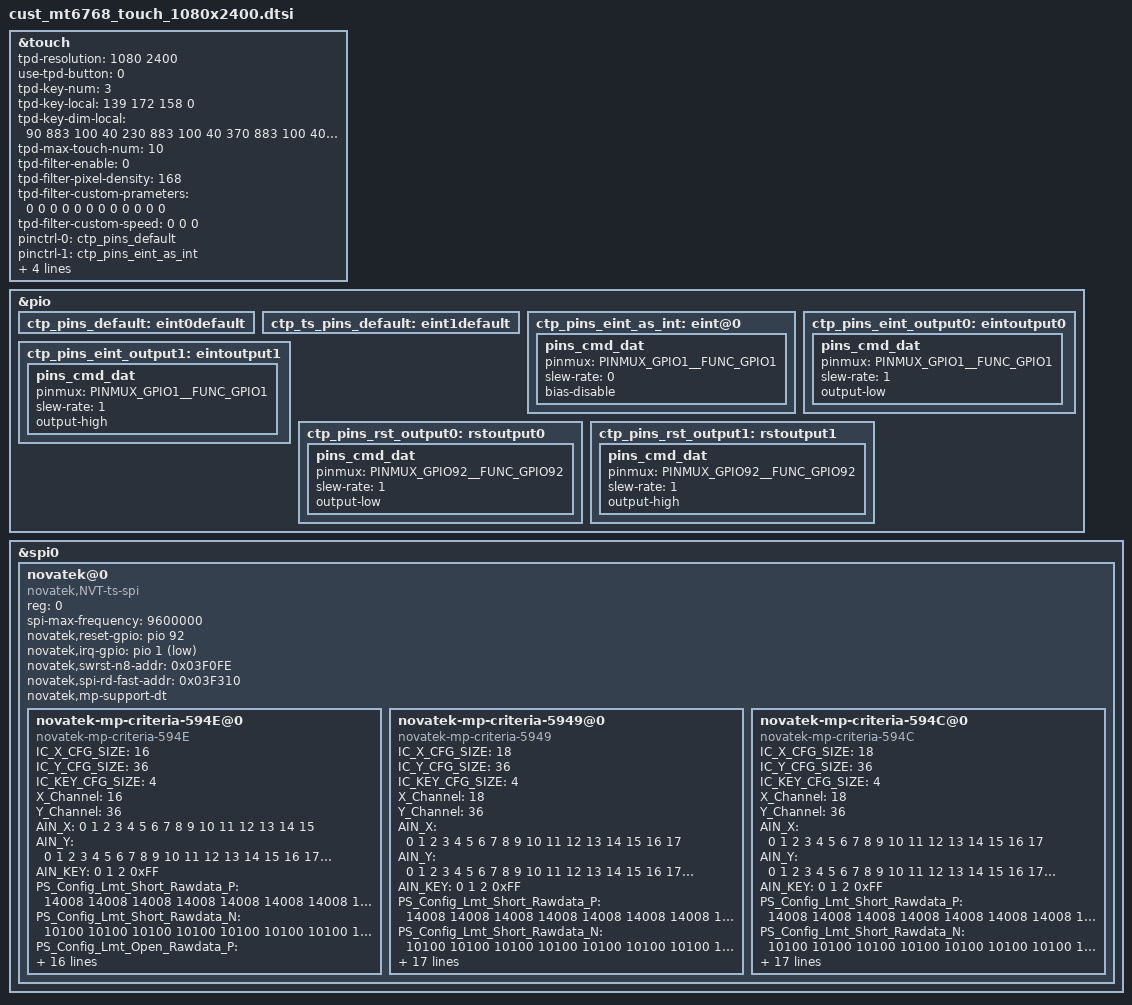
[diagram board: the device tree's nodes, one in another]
/*
 * Copyright (c) 2019 MediaTek Inc.
 *
 * This program is free software; you can redistribute it and/or modify
 * it under the terms of the GNU General Public License version 2 as
 * published by the Free Software Foundation.
 *
 * This program is distributed in the hope that it will be useful,
 * but WITHOUT ANY WARRANTY; without even the implied warranty of
 * MERCHANTABILITY or FITNESS FOR A PARTICULAR PURPOSE.  See the
 * GNU General Public License for more details.
 */
/* TOUCH start */

&touch {
	tpd-resolution = <1080 2400>;
	use-tpd-button = <0>;
	tpd-key-num = <3>;
	tpd-key-local= <139 172 158 0>;
	tpd-key-dim-local = <90 883 100 40 230
				883 100 40 370 883 100 40 0 0 0 0>;
	tpd-max-touch-num = <10>;
	tpd-filter-enable = <0>;
	tpd-filter-pixel-density = <168>;
	tpd-filter-custom-prameters = <0 0 0 0 0 0 0 0 0 0 0 0>;
	tpd-filter-custom-speed = <0 0 0>;
	pinctrl-names = "default", "state_eint_as_int",
		"state_eint_output0", "state_eint_output1",
		"state_rst_output0", "state_rst_output1";
	pinctrl-0 = <&ctp_pins_default>;
	pinctrl-1 = <&ctp_pins_eint_as_int>;
	pinctrl-2 = <&ctp_pins_eint_output0>;
	pinctrl-3 = <&ctp_pins_eint_output1>;
	pinctrl-4 = <&ctp_pins_rst_output0>;
	pinctrl-5 = <&ctp_pins_rst_output1>;
	status = "okay";
};
&pio {
	ctp_pins_default: eint0default {
	};
	ctp_ts_pins_default: eint1default {
	};
	ctp_pins_eint_as_int: eint@0 {
		pins_cmd_dat {
			pinmux = <PINMUX_GPIO1__FUNC_GPIO1>;
			slew-rate = <0>;
			bias-disable;
		};
	};
	ctp_pins_eint_output0: eintoutput0 {
		pins_cmd_dat {
			pinmux = <PINMUX_GPIO1__FUNC_GPIO1>;
			slew-rate = <1>;
			output-low;
		};
	};
	ctp_pins_eint_output1: eintoutput1 {
		pins_cmd_dat {
			pinmux = <PINMUX_GPIO1__FUNC_GPIO1>;
			slew-rate = <1>;
			output-high;
	};
	};
	ctp_pins_rst_output0: rstoutput0 {
		pins_cmd_dat {
				pinmux = <PINMUX_GPIO92__FUNC_GPIO92>;
				slew-rate = <1>;
				output-low;
			};
	};
	ctp_pins_rst_output1: rstoutput1 {
		pins_cmd_dat {
				pinmux = <PINMUX_GPIO92__FUNC_GPIO92>;
				slew-rate = <1>;
				output-high;
		};
	};

};

&spi0 {
	novatek@0 {
		compatible = "novatek,NVT-ts-spi","focaltech8719P,FTS-ts-spi";
		reg = <0>; //Same as CS ID
		status = "ok";

		spi-max-frequency = <9600000>;	//4800000,9600000,15000000,19200000
		novatek,reset-gpio = <&pio 92 0x00>;
		novatek,irq-gpio = <&pio 1 0x2001>;

		/* 525 */
		//novatek,swrst-n8-addr = <0x01F01A>;

		/* 672A, 525B, 675, 526, 672C */
		novatek,swrst-n8-addr = <0x03F0FE>;
		novatek,spi-rd-fast-addr = <0x03F310>;

		/* MP */
		novatek,mp-support-dt;

		/*36672C tr Module*/
		novatek-mp-criteria-594E@0 {
			#address-cells = <1>;
			#size-cells = <0>;
			compatible = "novatek-mp-criteria-594E";

			/* MP Config */
			IC_X_CFG_SIZE = <16>;
			IC_Y_CFG_SIZE = <36>;
			IC_KEY_CFG_SIZE = <4>;
			X_Channel = <16>;
			Y_Channel = <36>;
			AIN_X = <0 1 2 3 4 5 6 7 8 9 10 11 12 13 14 15>;
			AIN_Y = <0 1 2 3 4 5 6 7 8 9 10 11 12 13 14 15 16 17
						18 19 20 21 22 23 24 25 26 27 28 29 30 31 32 33 34 35>;
			AIN_KEY = <0 1 2 0xFF>;

			/* MP Criteria */
			PS_Config_Lmt_Short_Rawdata_P = <
				14008 14008 14008 14008 14008 14008 14008 14008 14008 14008 14008 14008 14008 14008 14008 14008
				14008 14008 14008 14008 14008 14008 14008 14008 14008 14008 14008 14008 14008 14008 14008 14008
				14008 14008 14008 14008 14008 14008 14008 14008 14008 14008 14008 14008 14008 14008 14008 14008
				14008 14008 14008 14008 14008 14008 14008 14008 14008 14008 14008 14008 14008 14008 14008 14008
				14008 14008 14008 14008 14008 14008 14008 14008 14008 14008 14008 14008 14008 14008 14008 14008
				14008 14008 14008 14008 14008 14008 14008 14008 14008 14008 14008 14008 14008 14008 14008 14008
				14008 14008 14008 14008 14008 14008 14008 14008 14008 14008 14008 14008 14008 14008 14008 14008
				14008 14008 14008 14008 14008 14008 14008 14008 14008 14008 14008 14008 14008 14008 14008 14008
				14008 14008 14008 14008 14008 14008 14008 14008 14008 14008 14008 14008 14008 14008 14008 14008
				14008 14008 14008 14008 14008 14008 14008 14008 14008 14008 14008 14008 14008 14008 14008 14008
				14008 14008 14008 14008 14008 14008 14008 14008 14008 14008 14008 14008 14008 14008 14008 14008
				14008 14008 14008 14008 14008 14008 14008 14008 14008 14008 14008 14008 14008 14008 14008 14008
				14008 14008 14008 14008 14008 14008 14008 14008 14008 14008 14008 14008 14008 14008 14008 14008
				14008 14008 14008 14008 14008 14008 14008 14008 14008 14008 14008 14008 14008 14008 14008 14008
				14008 14008 14008 14008 14008 14008 14008 14008 14008 14008 14008 14008 14008 14008 14008 14008
				14008 14008 14008 14008 14008 14008 14008 14008 14008 14008 14008 14008 14008 14008 14008 14008
				14008 14008 14008 14008 14008 14008 14008 14008 14008 14008 14008 14008 14008 14008 14008 14008
				14008 14008 14008 14008 14008 14008 14008 14008 14008 14008 14008 14008 14008 14008 14008 14008
				14008 14008 14008 14008 14008 14008 14008 14008 14008 14008 14008 14008 14008 14008 14008 14008
				14008 14008 14008 14008 14008 14008 14008 14008 14008 14008 14008 14008 14008 14008 14008 14008
				14008 14008 14008 14008 14008 14008 14008 14008 14008 14008 14008 14008 14008 14008 14008 14008
				14008 14008 14008 14008 14008 14008 14008 14008 14008 14008 14008 14008 14008 14008 14008 14008
				14008 14008 14008 14008 14008 14008 14008 14008 14008 14008 14008 14008 14008 14008 14008 14008
				14008 14008 14008 14008 14008 14008 14008 14008 14008 14008 14008 14008 14008 14008 14008 14008
				14008 14008 14008 14008 14008 14008 14008 14008 14008 14008 14008 14008 14008 14008 14008 14008
				14008 14008 14008 14008 14008 14008 14008 14008 14008 14008 14008 14008 14008 14008 14008 14008
				14008 14008 14008 14008 14008 14008 14008 14008 14008 14008 14008 14008 14008 14008 14008 14008
				14008 14008 14008 14008 14008 14008 14008 14008 14008 14008 14008 14008 14008 14008 14008 14008
				14008 14008 14008 14008 14008 14008 14008 14008 14008 14008 14008 14008 14008 14008 14008 14008
				14008 14008 14008 14008 14008 14008 14008 14008 14008 14008 14008 14008 14008 14008 14008 14008
				14008 14008 14008 14008 14008 14008 14008 14008 14008 14008 14008 14008 14008 14008 14008 14008
				14008 14008 14008 14008 14008 14008 14008 14008 14008 14008 14008 14008 14008 14008 14008 14008
				14008 14008 14008 14008 14008 14008 14008 14008 14008 14008 14008 14008 14008 14008 14008 14008
				14008 14008 14008 14008 14008 14008 14008 14008 14008 14008 14008 14008 14008 14008 14008 14008
				14008 14008 14008 14008 14008 14008 14008 14008 14008 14008 14008 14008 14008 14008 14008 14008
				14008 14008 14008 14008 14008 14008 14008 14008 14008 14008 14008 14008 14008 14008 14008 14008
				14008 14008 14008>;

			PS_Config_Lmt_Short_Rawdata_N = <
				10100 10100 10100 10100 10100 10100 10100 10100 10100 10100 10100 10100 10100 10100 10100 10100
				10100 10100 10100 10100 10100 10100 10100 10100 10100 10100 10100 10100 10100 10100 10100 10100
				10100 10100 10100 10100 10100 10100 10100 10100 10100 10100 10100 10100 10100 10100 10100 10100
				10100 10100 10100 10100 10100 10100 10100 10100 10100 10100 10100 10100 10100 10100 10100 10100
				10100 10100 10100 10100 10100 10100 10100 10100 10100 10100 10100 10100 10100 10100 10100 10100
				10100 10100 10100 10100 10100 10100 10100 10100 10100 10100 10100 10100 10100 10100 10100 10100
				10100 10100 10100 10100 10100 10100 10100 10100 10100 10100 10100 10100 10100 10100 10100 10100
				10100 10100 10100 10100 10100 10100 10100 10100 10100 10100 10100 10100 10100 10100 10100 10100
				10100 10100 10100 10100 10100 10100 10100 10100 10100 10100 10100 10100 10100 10100 10100 10100
				10100 10100 10100 10100 10100 10100 10100 10100 10100 10100 10100 10100 10100 10100 10100 10100
				10100 10100 10100 10100 10100 10100 10100 10100 10100 10100 10100 10100 10100 10100 10100 10100
				10100 10100 10100 10100 10100 10100 10100 10100 10100 10100 10100 10100 10100 10100 10100 10100
				10100 10100 10100 10100 10100 10100 10100 10100 10100 10100 10100 10100 10100 10100 10100 10100
				10100 10100 10100 10100 10100 10100 10100 10100 10100 10100 10100 10100 10100 10100 10100 10100
				10100 10100 10100 10100 10100 10100 10100 10100 10100 10100 10100 10100 10100 10100 10100 10100
				10100 10100 10100 10100 10100 10100 10100 10100 10100 10100 10100 10100 10100 10100 10100 10100
				10100 10100 10100 10100 10100 10100 10100 10100 10100 10100 10100 10100 10100 10100 10100 10100
				10100 10100 10100 10100 10100 10100 10100 10100 10100 10100 10100 10100 10100 10100 10100 10100
				10100 10100 10100 10100 10100 10100 10100 10100 10100 10100 10100 10100 10100 10100 10100 10100
				10100 10100 10100 10100 10100 10100 10100 10100 10100 10100 10100 10100 10100 10100 10100 10100
				10100 10100 10100 10100 10100 10100 10100 10100 10100 10100 10100 10100 10100 10100 10100 10100
				10100 10100 10100 10100 10100 10100 10100 10100 10100 10100 10100 10100 10100 10100 10100 10100
				10100 10100 10100 10100 10100 10100 10100 10100 10100 10100 10100 10100 10100 10100 10100 10100
				10100 10100 10100 10100 10100 10100 10100 10100 10100 10100 10100 10100 10100 10100 10100 10100
				10100 10100 10100 10100 10100 10100 10100 10100 10100 10100 10100 10100 10100 10100 10100 10100
				10100 10100 10100 10100 10100 10100 10100 10100 10100 10100 10100 10100 10100 10100 10100 10100
				10100 10100 10100 10100 10100 10100 10100 10100 10100 10100 10100 10100 10100 10100 10100 10100
				10100 10100 10100 10100 10100 10100 10100 10100 10100 10100 10100 10100 10100 10100 10100 10100
				10100 10100 10100 10100 10100 10100 10100 10100 10100 10100 10100 10100 10100 10100 10100 10100
				10100 10100 10100 10100 10100 10100 10100 10100 10100 10100 10100 10100 10100 10100 10100 10100
				10100 10100 10100 10100 10100 10100 10100 10100 10100 10100 10100 10100 10100 10100 10100 10100
				10100 10100 10100 10100 10100 10100 10100 10100 10100 10100 10100 10100 10100 10100 10100 10100
				10100 10100 10100 10100 10100 10100 10100 10100 10100 10100 10100 10100 10100 10100 10100 10100
				10100 10100 10100 10100 10100 10100 10100 10100 10100 10100 10100 10100 10100 10100 10100 10100
				10100 10100 10100 10100 10100 10100 10100 10100 10100 10100 10100 10100 10100 10100 10100 10100
				10100 10100 10100 10100 10100 10100 10100 10100 10100 10100 10100 10100 10100 10100 10100 10100
				10000 10000 10000>;

			PS_Config_Lmt_Open_Rawdata_P = <
				3693 4146 4086 4022 3992 3977 3984 3880 4044 4183 4170 4183 4118 4131 4132 3676
				3915 4151 4062 3997 3970 3959 3963 3906 4111 4198 4181 4205 4138 4152 4179 3911
				4102 4109 4018 3946 3922 3906 3915 3896 4050 4065 4058 4074 4023 4040 4085 4025
				4082 4088 3997 3914 3889 3871 3885 3829 4054 4078 4064 4085 4046 4060 4116 4025
				4015 4032 3931 3855 3838 3813 3826 3801 3953 3980 3976 3988 3948 3983 4030 3981
				3974 3994 3883 3824 3796 3773 3785 3760 3899 3927 3920 3931 3907 3945 3991 3945
				3976 4001 3897 3822 3801 3782 3791 3767 3901 3931 3918 3941 3918 3953 4009 3966
				3970 4005 3897 3817 3796 3782 3757 3766 3855 3886 3869 3889 3868 3907 3932 3922
				3956 3987 3883 3803 3785 3764 3782 3756 3802 3823 3813 3826 3819 3855 3925 3878
				3903 3934 3830 3747 3732 3711 3726 3700 3809 3827 3820 3831 3830 3868 3945 3894
				3879 3924 3809 3735 3714 3668 3710 3686 3771 3796 3788 3796 3799 3813 3913 3873
				3861 3897 3785 3712 3694 3676 3694 3672 3739 3767 3757 3766 3774 3823 3893 3857
				3833 3876 3771 3687 3668 3654 3666 3641 3677 3708 3693 3707 3721 3764 3843 3802
				3798 3840 3743 3656 3640 3627 3631 3606 3649 3679 3662 3680 3693 3739 3819 3780
				3764 3801 3708 3619 3579 3589 3602 3571 3621 3645 3638 3651 3644 3721 3801 3761
				3717 3749 3661 3572 3554 3539 3551 3523 3544 3567 3563 3571 3596 3648 3738 3693
				3658 3698 3609 3523 3505 3491 3500 3474 3533 3560 3551 3563 3581 3648 3729 3693
				3640 3679 3581 3476 3479 3465 3473 3452 3484 3512 3504 3488 3535 3606 3687 3652
				3606 3644 3556 3494 3474 3467 3472 3448 3393 3417 3409 3414 3439 3530 3627 3598
				3565 3598 3508 3446 3431 3424 3424 3407 3372 3395 3388 3400 3420 3512 3612 3586
				3533 3558 3469 3411 3397 3386 3389 3368 3312 3330 3330 3336 3358 3448 3560 3529
				3498 3518 3409 3374 3358 3343 3344 3326 3277 3292 3274 3304 3329 3418 3532 3504
				3458 3484 3389 3334 3323 3313 3308 3292 3183 3203 3208 3215 3236 3330 3446 3424
				3410 3430 3333 3277 3270 3262 3253 3241 3155 3175 3183 3186 3207 3304 3420 3402
				3364 3386 3291 3232 3225 3218 3214 3196 3101 3119 3119 3130 3152 3243 3371 3350
				3319 3322 3249 3186 3185 3179 3172 3155 3061 3063 3081 3092 3110 3203 3334 3313
				3283 3304 3208 3145 3147 3136 3134 3113 3010 3026 3032 3039 3056 3148 3280 3263
				3227 3243 3145 3084 3085 3074 3073 3053 2962 2976 2987 2991 3014 3103 3238 3224
				3158 3194 3092 3032 3036 3029 3024 3008 2892 2921 2926 2933 2952 3045 3173 3168
				3131 3154 3047 2989 2991 2986 2979 2966 2849 2871 2875 2882 2900 2994 3123 3124
				3101 3116 3015 2951 2961 2955 2949 2931 2795 2814 2816 2826 2844 2934 3066 3067
				3038 3053 2956 2889 2900 2895 2889 2871 2760 2780 2783 2791 2809 2898 3028 3038
				3059 3073 2969 2902 2916 2910 2906 2886 2748 2769 2774 2777 2797 2892 3024 3036
				2977 2993 2889 2822 2836 2830 2830 2814 2678 2695 2699 2699 2718 2818 2949 2961
				2702 2962 2851 2786 2805 2801 2800 2783 2672 2695 2693 2695 2714 2812 2952 2721
				2857 2920 2804 2739 2758 2755 2758 2742 2597 2622 2615 2618 2637 2737 2871 2847
				5120 5120 5120>;

			PS_Config_Lmt_Open_Rawdata_N = <
				1582 1777 1751 1723 1711 1704 1707 1663 1733 1792 1787 1792 1765 1770 1771 1575
				1678 1779 1741 1713 1701 1696 1698 1674 1762 1799 1792 1802 1773 1779 1791 1676
				1758 1761 1722 1691 1681 1674 1678 1669 1735 1742 1739 1746 1724 1731 1750 1725
				1749 1752 1713 1677 1666 1659 1665 1641 1737 1747 1741 1750 1734 1740 1764 1725
				1720 1728 1684 1652 1645 1634 1639 1629 1694 1705 1704 1709 1692 1707 1727 1706
				1703 1711 1664 1639 1627 1617 1622 1611 1671 1683 1680 1684 1674 1690 1710 1690
				1704 1714 1670 1638 1629 1621 1624 1614 1672 1684 1679 1689 1679 1694 1718 1699
				1701 1716 1670 1636 1627 1621 1610 1614 1652 1665 1658 1666 1657 1674 1685 1681
				1695 1708 1664 1630 1622 1613 1621 1609 1629 1638 1634 1639 1636 1652 1682 1662
				1672 1686 1641 1606 1599 1590 1597 1585 1632 1640 1637 1642 1641 1657 1690 1669
				1662 1681 1632 1600 1591 1572 1590 1579 1616 1627 1623 1627 1628 1634 1677 1660
				1654 1670 1622 1591 1583 1575 1583 1573 1602 1614 1610 1614 1617 1638 1668 1653
				1642 1661 1616 1580 1572 1566 1571 1560 1576 1589 1582 1588 1594 1613 1647 1629
				1627 1645 1604 1567 1560 1554 1556 1545 1564 1576 1569 1577 1582 1602 1636 1620
				1613 1629 1589 1551 1534 1538 1543 1530 1552 1562 1559 1564 1561 1594 1629 1612
				1593 1606 1569 1531 1523 1516 1522 1510 1519 1528 1527 1530 1541 1563 1602 1582
				1567 1585 1546 1510 1502 1496 1500 1489 1514 1525 1522 1527 1534 1563 1598 1582
				1560 1576 1534 1489 1491 1485 1488 1479 1493 1505 1501 1495 1515 1545 1580 1565
				1545 1561 1524 1497 1489 1486 1488 1477 1454 1464 1461 1463 1474 1513 1554 1542
				1528 1542 1503 1477 1470 1467 1467 1460 1445 1455 1452 1457 1465 1505 1548 1537
				1514 1525 1486 1462 1456 1451 1452 1443 1419 1427 1427 1429 1439 1477 1525 1512
				1499 1507 1461 1446 1439 1432 1433 1425 1404 1411 1403 1416 1426 1465 1513 1501
				1482 1493 1452 1429 1424 1420 1417 1411 1364 1372 1375 1378 1387 1427 1477 1467
				1461 1470 1428 1404 1401 1398 1394 1389 1352 1360 1364 1365 1374 1416 1465 1458
				1441 1451 1410 1385 1382 1379 1377 1369 1329 1336 1336 1341 1351 1390 1444 1435
				1422 1423 1392 1365 1365 1362 1359 1352 1312 1312 1320 1325 1333 1372 1429 1420
				1407 1416 1375 1348 1348 1344 1343 1334 1290 1297 1299 1302 1309 1349 1405 1398
				1383 1390 1348 1321 1322 1317 1317 1308 1269 1275 1280 1282 1291 1330 1387 1381
				1353 1369 1325 1299 1301 1298 1296 1289 1239 1252 1254 1257 1265 1305 1360 1357
				1342 1351 1306 1281 1282 1279 1276 1271 1221 1230 1232 1235 1243 1283 1338 1339
				1329 1335 1292 1264 1269 1266 1264 1256 1198 1206 1207 1211 1219 1257 1314 1314
				1302 1308 1267 1238 1243 1240 1238 1230 1183 1191 1192 1196 1204 1242 1297 1302
				1311 1317 1272 1243 1249 1247 1245 1237 1177 1186 1189 1190 1198 1239 1296 1301
				1276 1282 1238 1209 1215 1213 1213 1206 1147 1155 1156 1156 1165 1207 1264 1269
				1158 1269 1222 1194 1202 1200 1200 1192 1145 1155 1154 1155 1163 1205 1265 1166
				1224 1251 1201 1174 1182 1180 1182 1175 1113 1123 1120 1122 1130 1173 1230 1220
				(-511) (-511) (-511)>;

			PS_Config_Lmt_FW_Rawdata_P = <
				1125 1124 1125 1122 1121 1127 1125 1127 1104 1106 1107 1114 1110 1106 1101 1114
				1118 1111 1110 1114 1113 1117 1120 1118 1120 1115 1115 1106 1104 1101 1097 1115
				1125 1108 1113 1118 1113 1113 1115 1108 1120 1106 1114 1117 1111 1124 1118 1099
				1100 1132 1131 1136 1120 1118 1141 1127 1099 1106 1103 1085 1089 1118 1122 1087
				1139 1124 1120 1132 1114 1106 1129 1120 1117 1121 1122 1125 1125 1121 1117 1113
				1120 1117 1115 1113 1104 1106 1111 1114 1114 1107 1129 1120 1115 1125 1131 1110
				1110 1131 1122 1121 1113 1117 1114 1114 1103 1104 1125 1125 1125 1131 1134 1097
				1132 1111 1111 1110 1114 1114 1110 1113 1129 1134 1124 1129 1134 1120 1115 1120
				1135 1122 1122 1120 1115 1111 1120 1114 1136 1132 1124 1120 1124 1125 1118 1127
				1129 1117 1113 1110 1121 1117 1120 1125 1101 1111 1118 1121 1118 1129 1125 1104
				1114 1113 1111 1111 1111 1107 1117 1118 1122 1124 1125 1125 1122 1132 1124 1128
				1108 1125 1129 1127 1127 1122 1121 1118 1132 1132 1122 1125 1120 1124 1115 1131
				1129 1115 1121 1113 1115 1113 1113 1113 1139 1135 1132 1131 1128 1134 1121 1125
				1103 1148 1155 1145 1134 1149 1156 1155 1122 1127 1122 1108 1121 1125 1120 1121
				1132 1121 1118 1117 1129 1114 1120 1122 1127 1118 1111 1117 1104 1104 1103 1121
				1099 1122 1110 1118 1111 1103 1113 1106 1107 1106 1104 1108 1106 1096 1096 1101
				1111 1108 1114 1107 1111 1106 1114 1113 1138 1132 1127 1134 1124 1131 1121 1146
				1121 1122 1129 1128 1115 1121 1129 1115 1096 1097 1111 1129 1110 1111 1134 1108
				1117 1117 1122 1121 1124 1118 1114 1115 1120 1106 1104 1108 1107 1107 1111 1127
				1135 1124 1122 1125 1125 1134 1135 1124 1117 1110 1121 1118 1121 1115 1120 1107
				1106 1103 1110 1110 1103 1108 1103 1108 1141 1104 1100 1099 1097 1099 1097 1138
				1131 1113 1132 1115 1115 1124 1134 1129 1113 1114 1114 1111 1110 1113 1111 1120
				1129 1104 1099 1104 1104 1100 1106 1103 1100 1125 1118 1118 1121 1117 1114 1106
				1118 1117 1117 1120 1117 1118 1120 1129 1128 1132 1122 1124 1124 1128 1125 1115
				1122 1097 1092 1093 1096 1094 1096 1099 1120 1110 1120 1111 1108 1108 1113 1120
				1111 1135 1129 1135 1131 1129 1127 1107 1106 1106 1101 1100 1100 1108 1103 1110
				1135 1120 1122 1121 1121 1127 1125 1129 1134 1122 1128 1117 1120 1120 1118 1136
				1108 1124 1121 1118 1124 1117 1110 1101 1111 1111 1115 1113 1115 1118 1118 1120
				1111 1106 1101 1099 1113 1104 1103 1118 1115 1118 1115 1124 1117 1113 1121 1115
				1124 1129 1129 1131 1125 1138 1131 1108 1121 1121 1125 1118 1114 1117 1121 1124
				1111 1114 1110 1111 1107 1113 1107 1106 1113 1113 1114 1106 1115 1107 1107 1125
				1106 1090 1080 1083 1085 1087 1083 1131 1115 1149 1150 1146 1149 1146 1142 1108
				1115 1121 1122 1124 1127 1122 1118 1108 1111 1135 1131 1117 1128 1122 1122 1127
				1103 1129 1120 1115 1122 1101 1099 1106 1114 1111 1117 1129 1127 1136 1129 1107
				1141 1134 1141 1141 1139 1141 1139 1124 1124 1108 1103 1122 1120 1120 1118 1113
				1092 1113 1118 1106 1115 1127 1111 1097 1118 1118 1117 1124 1122 1115 1117 1107
				2560 2560 2560>;

			PS_Config_Lmt_FW_Rawdata_N = <
				482 481 482 481 480 483 482 483 473 474 474 477 475 474 472 477
				479 476 475 477 477 478 480 479 480 478 478 474 473 472 470 478
				482 475 477 479 477 477 478 475 480 474 477 478 476 481 479 471
				471 485 484 487 480 479 489 483 471 474 472 465 466 479 481 466
				488 481 480 485 477 474 484 480 478 480 481 482 482 480 478 477
				480 478 478 477 473 474 476 477 477 474 484 480 478 482 484 475
				475 484 481 480 477 478 477 477 472 473 482 482 482 484 486 470
				485 476 476 475 477 477 475 477 484 486 481 484 486 480 478 480
				486 481 481 480 478 476 480 477 487 485 481 480 481 482 479 483
				484 478 477 475 480 478 480 482 472 476 479 480 479 484 482 473
				477 477 476 476 476 474 478 479 481 481 482 482 481 485 481 483
				475 482 484 483 483 481 480 479 485 485 481 482 480 481 478 484
				484 478 480 477 478 477 477 477 488 486 485 484 483 486 480 482
				472 492 495 490 486 492 495 495 481 483 481 475 480 482 480 480
				485 480 479 478 484 477 480 481 483 479 476 478 473 473 472 480
				471 481 475 479 476 472 477 474 474 474 473 475 474 469 469 472
				476 475 477 474 476 474 477 477 487 485 483 486 481 484 480 491
				480 481 484 483 478 480 484 478 469 470 476 484 475 476 486 475
				478 478 481 480 481 479 477 478 480 474 473 475 474 474 476 483
				486 481 481 482 482 486 486 481 478 475 480 479 480 478 480 474
				474 472 475 475 472 475 472 475 489 473 471 471 470 471 470 487
				484 477 485 478 478 481 486 484 477 477 477 476 475 477 476 480
				484 473 471 473 473 471 474 472 471 482 479 479 480 478 477 474
				479 478 478 480 478 479 480 484 483 485 481 481 481 483 482 478
				481 470 468 468 469 469 469 471 480 475 480 476 475 475 477 480
				476 486 484 486 484 484 483 474 474 474 472 471 471 475 472 475
				486 480 481 480 480 483 482 484 486 481 483 478 480 480 479 487
				475 481 480 479 481 478 475 472 476 476 478 477 478 479 479 480
				476 474 472 471 477 473 472 479 478 479 478 481 478 477 480 478
				481 484 484 484 482 487 484 475 480 480 482 479 477 478 480 481
				476 477 475 476 474 477 474 474 477 477 477 474 478 474 474 482
				474 467 463 464 465 466 464 484 478 492 493 491 492 491 489 475
				478 480 481 481 483 481 479 475 476 486 484 478 483 481 481 483
				472 484 480 478 481 472 471 474 477 476 478 484 483 487 484 474
				489 486 489 489 488 489 488 481 481 475 472 481 480 480 479 477
				468 477 479 474 478 483 476 470 479 479 478 481 481 478 478 474
				240 240 240>;

			PS_Config_Lmt_FW_CC_P = <
				41 40 40 40 40 40 40 40 40 40 40 40 40 40 40 41
				41 40 40 40 40 40 40 40 40 40 40 40 40 40 40 40
				40 40 40 40 40 40 40 40 40 40 40 40 40 40 40 40
				41 40 40 40 40 40 40 40 40 40 40 40 40 40 40 40
				40 40 40 40 40 40 40 40 40 40 40 40 40 40 40 40
				41 40 40 40 40 40 40 40 40 40 40 40 40 40 40 40
				40 40 40 40 40 40 40 40 40 40 40 40 40 40 40 41
				41 41 40 41 40 40 41 41 40 40 40 40 40 40 40 40
				41 40 40 40 40 40 40 41 40 40 40 40 40 40 40 41
				41 41 41 41 41 41 41 41 40 40 40 40 40 40 40 40
				41 40 40 40 40 40 40 40 41 41 41 41 41 40 40 41
				41 40 40 40 40 40 41 41 40 40 40 40 40 40 40 40
				41 40 40 40 40 40 40 40 40 40 40 40 40 40 40 41
				41 40 40 40 41 40 41 41 41 41 40 41 40 40 40 40
				41 40 41 40 41 40 41 41 41 41 40 41 41 41 40 41
				41 41 41 41 41 41 41 41 41 41 40 40 40 41 40 41
				40 40 40 40 40 40 40 40 41 41 41 41 41 41 41 41
				41 40 40 40 41 41 41 41 41 41 41 40 41 41 40 41
				41 40 40 40 40 41 41 41 41 41 41 40 40 40 40 41
				41 41 41 41 41 41 41 41 41 41 41 41 41 41 41 41
				40 40 40 40 40 40 40 40 41 41 40 40 40 40 40 41
				41 41 41 41 41 41 41 41 41 41 41 41 41 41 41 41
				41 40 40 40 40 40 40 41 41 40 40 40 40 40 40 41
				41 41 41 41 41 41 41 41 40 40 40 40 40 40 40 41
				41 40 40 40 40 40 40 40 41 40 40 40 40 40 40 41
				41 41 41 41 41 41 41 41 41 41 41 41 41 41 41 41
				41 40 40 40 40 41 41 41 41 41 41 41 41 41 41 41
				41 41 41 41 41 41 41 41 41 41 41 41 41 41 41 41
				41 41 41 41 41 41 41 41 41 41 41 40 41 41 41 41
				41 41 41 41 41 41 41 41 41 41 41 41 41 41 41 41
				41 41 41 41 41 41 41 41 41 41 41 41 41 41 41 41
				41 41 41 41 41 41 41 41 41 41 41 40 41 41 40 41
				41 41 41 41 41 41 41 41 41 41 41 41 41 41 41 41
				41 41 41 41 41 41 41 41 41 41 41 40 41 40 40 41
				41 40 41 41 41 41 41 41 41 41 41 41 41 41 41 41
				42 41 41 41 41 41 41 42 41 41 41 41 41 41 41 42
				314 314 314>;

			PS_Config_Lmt_FW_CC_N = <
				18 17 17 17 17 17 17 17 17 17 17 17 17 17 17 18
				18 17 17 17 17 17 17 17 17 17 17 17 17 17 17 17
				17 17 17 17 17 17 17 17 17 17 17 17 17 17 17 17
				18 17 17 17 17 17 17 17 17 17 17 17 17 17 17 17
				17 17 17 17 17 17 17 17 17 17 17 17 17 17 17 17
				18 17 17 17 17 17 17 17 17 17 17 17 17 17 17 17
				17 17 17 17 17 17 17 17 17 17 17 17 17 17 17 18
				18 18 17 18 17 17 18 18 17 17 17 17 17 17 17 17
				18 17 17 17 17 17 17 18 17 17 17 17 17 17 17 18
				18 18 18 18 18 18 18 18 17 17 17 17 17 17 17 17
				18 17 17 17 17 17 17 17 18 18 18 18 18 17 17 18
				18 17 17 17 17 17 18 18 17 17 17 17 17 17 17 17
				18 17 17 17 17 17 17 17 17 17 17 17 17 17 17 18
				18 17 17 17 18 17 18 18 18 18 17 18 17 17 17 17
				18 17 18 17 18 17 18 18 18 18 17 18 18 18 17 18
				18 18 18 18 18 18 18 18 18 18 17 17 17 18 17 18
				17 17 17 17 17 17 17 17 18 18 18 18 18 18 18 18
				18 17 17 17 18 18 18 18 18 18 18 17 18 18 17 18
				18 17 17 17 17 18 18 18 18 18 18 17 17 17 17 18
				18 18 18 18 18 18 18 18 18 18 18 18 18 18 18 18
				17 17 17 17 17 17 17 17 18 18 17 17 17 17 17 18
				18 18 18 18 18 18 18 18 18 18 18 18 18 18 18 18
				18 17 17 17 17 17 17 18 18 17 17 17 17 17 17 18
				18 18 18 18 18 18 18 18 17 17 17 17 17 17 17 18
				18 17 17 17 17 17 17 17 18 17 17 17 17 17 17 18
				18 18 18 18 18 18 18 18 18 18 18 18 18 18 18 18
				18 17 17 17 17 18 18 18 18 18 18 18 18 18 18 18
				18 18 18 18 18 18 18 18 18 18 18 18 18 18 18 18
				18 18 18 18 18 18 18 18 18 18 18 17 18 18 18 18
				18 18 18 18 18 18 18 18 18 18 18 18 18 18 18 18
				18 18 18 18 18 18 18 18 18 18 18 18 18 18 18 18
				18 18 18 18 18 18 18 18 18 18 18 17 18 18 17 18
				18 18 18 18 18 18 18 18 18 18 18 18 18 18 18 18
				18 18 18 18 18 18 18 18 18 18 18 17 18 17 17 18
				18 17 18 18 18 18 18 18 18 18 18 18 18 18 18 18
				19 18 18 18 18 18 18 19 18 18 18 18 18 18 18 19
				0 0 0>;

			PS_Config_Lmt_FW_Diff_P = <
				50 50 50 50 50 50 50 50 50 50 50 50 50 50 50 50
				50 50 50 50 50 50 50 50 50 50 50 50 50 50 50 50
				50 50 50 50 50 50 50 50 50 50 50 50 50 50 50 50
				50 50 50 50 50 50 50 50 50 50 50 50 50 50 50 50
				50 50 50 50 50 50 50 50 50 50 50 50 50 50 50 50
				50 50 50 50 50 50 50 50 50 50 50 50 50 50 50 50
				50 50 50 50 50 50 50 50 50 50 50 50 50 50 50 50
				50 50 50 50 50 50 50 50 50 50 50 50 50 50 50 50
				50 50 50 50 50 50 50 50 50 50 50 50 50 50 50 50
				50 50 50 50 50 50 50 50 50 50 50 50 50 50 50 50
				50 50 50 50 50 50 50 50 50 50 50 50 50 50 50 50
				50 50 50 50 50 50 50 50 50 50 50 50 50 50 50 50
				50 50 50 50 50 50 50 50 50 50 50 50 50 50 50 50
				50 50 50 50 50 50 50 50 50 50 50 50 50 50 50 50
				50 50 50 50 50 50 50 50 50 50 50 50 50 50 50 50
				50 50 50 50 50 50 50 50 50 50 50 50 50 50 50 50
				50 50 50 50 50 50 50 50 50 50 50 50 50 50 50 50
				50 50 50 50 50 50 50 50 50 50 50 50 50 50 50 50
				50 50 50 50 50 50 50 50 50 50 50 50 50 50 50 50
				50 50 50 50 50 50 50 50 50 50 50 50 50 50 50 50
				50 50 50 50 50 50 50 50 50 50 50 50 50 50 50 50
				50 50 50 50 50 50 50 50 50 50 50 50 50 50 50 50
				50 50 50 50 50 50 50 50 50 50 50 50 50 50 50 50
				50 50 50 50 50 50 50 50 50 50 50 50 50 50 50 50
				50 50 50 50 50 50 50 50 50 50 50 50 50 50 50 50
				50 50 50 50 50 50 50 50 50 50 50 50 50 50 50 50
				50 50 50 50 50 50 50 50 50 50 50 50 50 50 50 50
				50 50 50 50 50 50 50 50 50 50 50 50 50 50 50 50
				50 50 50 50 50 50 50 50 50 50 50 50 50 50 50 50
				50 50 50 50 50 50 50 50 50 50 50 50 50 50 50 50
				50 50 50 50 50 50 50 50 50 50 50 50 50 50 50 50
				50 50 50 50 50 50 50 50 50 50 50 50 50 50 50 50
				50 50 50 50 50 50 50 50 50 50 50 50 50 50 50 50
				50 50 50 50 50 50 50 50 50 50 50 50 50 50 50 50
				50 50 50 50 50 50 50 50 50 50 50 50 50 50 50 50
				50 50 50 50 50 50 50 50 50 50 50 50 50 50 50 50
				75 75 75>;

			PS_Config_Lmt_FW_Diff_N = <
				(-50) (-50) (-50) (-50) (-50) (-50) (-50) (-50) (-50) (-50) (-50) (-50) (-50) (-50) (-50) (-50)
				(-50) (-50) (-50) (-50) (-50) (-50) (-50) (-50) (-50) (-50) (-50) (-50) (-50) (-50) (-50) (-50)
				(-50) (-50) (-50) (-50) (-50) (-50) (-50) (-50) (-50) (-50) (-50) (-50) (-50) (-50) (-50) (-50)
				(-50) (-50) (-50) (-50) (-50) (-50) (-50) (-50) (-50) (-50) (-50) (-50) (-50) (-50) (-50) (-50)
				(-50) (-50) (-50) (-50) (-50) (-50) (-50) (-50) (-50) (-50) (-50) (-50) (-50) (-50) (-50) (-50)
				(-50) (-50) (-50) (-50) (-50) (-50) (-50) (-50) (-50) (-50) (-50) (-50) (-50) (-50) (-50) (-50)
				(-50) (-50) (-50) (-50) (-50) (-50) (-50) (-50) (-50) (-50) (-50) (-50) (-50) (-50) (-50) (-50)
				(-50) (-50) (-50) (-50) (-50) (-50) (-50) (-50) (-50) (-50) (-50) (-50) (-50) (-50) (-50) (-50)
				(-50) (-50) (-50) (-50) (-50) (-50) (-50) (-50) (-50) (-50) (-50) (-50) (-50) (-50) (-50) (-50)
				(-50) (-50) (-50) (-50) (-50) (-50) (-50) (-50) (-50) (-50) (-50) (-50) (-50) (-50) (-50) (-50)
				(-50) (-50) (-50) (-50) (-50) (-50) (-50) (-50) (-50) (-50) (-50) (-50) (-50) (-50) (-50) (-50)
				(-50) (-50) (-50) (-50) (-50) (-50) (-50) (-50) (-50) (-50) (-50) (-50) (-50) (-50) (-50) (-50)
				(-50) (-50) (-50) (-50) (-50) (-50) (-50) (-50) (-50) (-50) (-50) (-50) (-50) (-50) (-50) (-50)
				(-50) (-50) (-50) (-50) (-50) (-50) (-50) (-50) (-50) (-50) (-50) (-50) (-50) (-50) (-50) (-50)
				(-50) (-50) (-50) (-50) (-50) (-50) (-50) (-50) (-50) (-50) (-50) (-50) (-50) (-50) (-50) (-50)
				(-50) (-50) (-50) (-50) (-50) (-50) (-50) (-50) (-50) (-50) (-50) (-50) (-50) (-50) (-50) (-50)
				(-50) (-50) (-50) (-50) (-50) (-50) (-50) (-50) (-50) (-50) (-50) (-50) (-50) (-50) (-50) (-50)
				(-50) (-50) (-50) (-50) (-50) (-50) (-50) (-50) (-50) (-50) (-50) (-50) (-50) (-50) (-50) (-50)
				(-50) (-50) (-50) (-50) (-50) (-50) (-50) (-50) (-50) (-50) (-50) (-50) (-50) (-50) (-50) (-50)
				(-50) (-50) (-50) (-50) (-50) (-50) (-50) (-50) (-50) (-50) (-50) (-50) (-50) (-50) (-50) (-50)
				(-50) (-50) (-50) (-50) (-50) (-50) (-50) (-50) (-50) (-50) (-50) (-50) (-50) (-50) (-50) (-50)
				(-50) (-50) (-50) (-50) (-50) (-50) (-50) (-50) (-50) (-50) (-50) (-50) (-50) (-50) (-50) (-50)
				(-50) (-50) (-50) (-50) (-50) (-50) (-50) (-50) (-50) (-50) (-50) (-50) (-50) (-50) (-50) (-50)
				(-50) (-50) (-50) (-50) (-50) (-50) (-50) (-50) (-50) (-50) (-50) (-50) (-50) (-50) (-50) (-50)
				(-50) (-50) (-50) (-50) (-50) (-50) (-50) (-50) (-50) (-50) (-50) (-50) (-50) (-50) (-50) (-50)
				(-50) (-50) (-50) (-50) (-50) (-50) (-50) (-50) (-50) (-50) (-50) (-50) (-50) (-50) (-50) (-50)
				(-50) (-50) (-50) (-50) (-50) (-50) (-50) (-50) (-50) (-50) (-50) (-50) (-50) (-50) (-50) (-50)
				(-50) (-50) (-50) (-50) (-50) (-50) (-50) (-50) (-50) (-50) (-50) (-50) (-50) (-50) (-50) (-50)
				(-50) (-50) (-50) (-50) (-50) (-50) (-50) (-50) (-50) (-50) (-50) (-50) (-50) (-50) (-50) (-50)
				(-50) (-50) (-50) (-50) (-50) (-50) (-50) (-50) (-50) (-50) (-50) (-50) (-50) (-50) (-50) (-50)
				(-50) (-50) (-50) (-50) (-50) (-50) (-50) (-50) (-50) (-50) (-50) (-50) (-50) (-50) (-50) (-50)
				(-50) (-50) (-50) (-50) (-50) (-50) (-50) (-50) (-50) (-50) (-50) (-50) (-50) (-50) (-50) (-50)
				(-50) (-50) (-50) (-50) (-50) (-50) (-50) (-50) (-50) (-50) (-50) (-50) (-50) (-50) (-50) (-50)
				(-50) (-50) (-50) (-50) (-50) (-50) (-50) (-50) (-50) (-50) (-50) (-50) (-50) (-50) (-50) (-50)
				(-50) (-50) (-50) (-50) (-50) (-50) (-50) (-50) (-50) (-50) (-50) (-50) (-50) (-50) (-50) (-50)
				(-50) (-50) (-50) (-50) (-50) (-50) (-50) (-50) (-50) (-50) (-50) (-50) (-50) (-50) (-50) (-50)
				(-75) (-75) (-75)>;

			PS_Config_Diff_Test_Frame = <50>;
		};/*36672C tr Module*/

		/*36672C tm Module*/
		novatek-mp-criteria-5949@0 {
			#address-cells = <1>;
			#size-cells = <0>;
			compatible = "novatek-mp-criteria-5949";

			/* MP Config */
			IC_X_CFG_SIZE = <18>;
			IC_Y_CFG_SIZE = <36>;
			IC_KEY_CFG_SIZE = <4>;
			X_Channel = <18>;
			Y_Channel = <36>;
			AIN_X = <0 1 2 3 4 5 6 7 8 9 10 11 12 13 14 15 16 17>;
			AIN_Y = <0 1 2 3 4 5 6 7 8 9 10 11 12 13 14 15 16 17
						18 19 20 21 22 23 24 25 26 27 28 29 30 31 32 33 34 35>;
			AIN_KEY = <0 1 2 0xFF>;

			/* MP Criteria */
			PS_Config_Lmt_Short_Rawdata_P = <
				14008 14008 14008 14008 14008 14008 14008 14008 14008 14008 14008 14008 14008 14008 14008 14008 14008 14008
				14008 14008 14008 14008 14008 14008 14008 14008 14008 14008 14008 14008 14008 14008 14008 14008 14008 14008
				14008 14008 14008 14008 14008 14008 14008 14008 14008 14008 14008 14008 14008 14008 14008 14008 14008 14008
				14008 14008 14008 14008 14008 14008 14008 14008 14008 14008 14008 14008 14008 14008 14008 14008 14008 14008
				14008 14008 14008 14008 14008 14008 14008 14008 14008 14008 14008 14008 14008 14008 14008 14008 14008 14008
				14008 14008 14008 14008 14008 14008 14008 14008 14008 14008 14008 14008 14008 14008 14008 14008 14008 14008
				14008 14008 14008 14008 14008 14008 14008 14008 14008 14008 14008 14008 14008 14008 14008 14008 14008 14008
				14008 14008 14008 14008 14008 14008 14008 14008 14008 14008 14008 14008 14008 14008 14008 14008 14008 14008
				14008 14008 14008 14008 14008 14008 14008 14008 14008 14008 14008 14008 14008 14008 14008 14008 14008 14008
				14008 14008 14008 14008 14008 14008 14008 14008 14008 14008 14008 14008 14008 14008 14008 14008 14008 14008
				14008 14008 14008 14008 14008 14008 14008 14008 14008 14008 14008 14008 14008 14008 14008 14008 14008 14008
				14008 14008 14008 14008 14008 14008 14008 14008 14008 14008 14008 14008 14008 14008 14008 14008 14008 14008
				14008 14008 14008 14008 14008 14008 14008 14008 14008 14008 14008 14008 14008 14008 14008 14008 14008 14008
				14008 14008 14008 14008 14008 14008 14008 14008 14008 14008 14008 14008 14008 14008 14008 14008 14008 14008
				14008 14008 14008 14008 14008 14008 14008 14008 14008 14008 14008 14008 14008 14008 14008 14008 14008 14008
				14008 14008 14008 14008 14008 14008 14008 14008 14008 14008 14008 14008 14008 14008 14008 14008 14008 14008
				14008 14008 14008 14008 14008 14008 14008 14008 14008 14008 14008 14008 14008 14008 14008 14008 14008 14008
				14008 14008 14008 14008 14008 14008 14008 14008 14008 14008 14008 14008 14008 14008 14008 14008 14008 14008
				14008 14008 14008 14008 14008 14008 14008 14008 14008 14008 14008 14008 14008 14008 14008 14008 14008 14008
				14008 14008 14008 14008 14008 14008 14008 14008 14008 14008 14008 14008 14008 14008 14008 14008 14008 14008
				14008 14008 14008 14008 14008 14008 14008 14008 14008 14008 14008 14008 14008 14008 14008 14008 14008 14008
				14008 14008 14008 14008 14008 14008 14008 14008 14008 14008 14008 14008 14008 14008 14008 14008 14008 14008
				14008 14008 14008 14008 14008 14008 14008 14008 14008 14008 14008 14008 14008 14008 14008 14008 14008 14008
				14008 14008 14008 14008 14008 14008 14008 14008 14008 14008 14008 14008 14008 14008 14008 14008 14008 14008
				14008 14008 14008 14008 14008 14008 14008 14008 14008 14008 14008 14008 14008 14008 14008 14008 14008 14008
				14008 14008 14008 14008 14008 14008 14008 14008 14008 14008 14008 14008 14008 14008 14008 14008 14008 14008
				14008 14008 14008 14008 14008 14008 14008 14008 14008 14008 14008 14008 14008 14008 14008 14008 14008 14008
				14008 14008 14008 14008 14008 14008 14008 14008 14008 14008 14008 14008 14008 14008 14008 14008 14008 14008
				14008 14008 14008 14008 14008 14008 14008 14008 14008 14008 14008 14008 14008 14008 14008 14008 14008 14008
				14008 14008 14008 14008 14008 14008 14008 14008 14008 14008 14008 14008 14008 14008 14008 14008 14008 14008
				14008 14008 14008 14008 14008 14008 14008 14008 14008 14008 14008 14008 14008 14008 14008 14008 14008 14008
				14008 14008 14008 14008 14008 14008 14008 14008 14008 14008 14008 14008 14008 14008 14008 14008 14008 14008
				14008 14008 14008 14008 14008 14008 14008 14008 14008 14008 14008 14008 14008 14008 14008 14008 14008 14008
				14008 14008 14008 14008 14008 14008 14008 14008 14008 14008 14008 14008 14008 14008 14008 14008 14008 14008
				14008 14008 14008 14008 14008 14008 14008 14008 14008 14008 14008 14008 14008 14008 14008 14008 14008 14008
				14008 14008 14008 14008 14008 14008 14008 14008 14008 14008 14008 14008 14008 14008 14008 14008 14008 14008
				14008 14008 14008>;

			PS_Config_Lmt_Short_Rawdata_N = <
				10100 10100 10100 10100 10100 10100 10100 10100 10100 10100 10100 10100 10100 10100 10100 10100 10100 10100
				10100 10100 10100 10100 10100 10100 10100 10100 10100 10100 10100 10100 10100 10100 10100 10100 10100 10100
				10100 10100 10100 10100 10100 10100 10100 10100 10100 10100 10100 10100 10100 10100 10100 10100 10100 10100
				10100 10100 10100 10100 10100 10100 10100 10100 10100 10100 10100 10100 10100 10100 10100 10100 10100 10100
				10100 10100 10100 10100 10100 10100 10100 10100 10100 10100 10100 10100 10100 10100 10100 10100 10100 10100
				10100 10100 10100 10100 10100 10100 10100 10100 10100 10100 10100 10100 10100 10100 10100 10100 10100 10100
				10100 10100 10100 10100 10100 10100 10100 10100 10100 10100 10100 10100 10100 10100 10100 10100 10100 10100
				10100 10100 10100 10100 10100 10100 10100 10100 10100 10100 10100 10100 10100 10100 10100 10100 10100 10100
				10100 10100 10100 10100 10100 10100 10100 10100 10100 10100 10100 10100 10100 10100 10100 10100 10100 10100
				10100 10100 10100 10100 10100 10100 10100 10100 10100 10100 10100 10100 10100 10100 10100 10100 10100 10100
				10100 10100 10100 10100 10100 10100 10100 10100 10100 10100 10100 10100 10100 10100 10100 10100 10100 10100
				10100 10100 10100 10100 10100 10100 10100 10100 10100 10100 10100 10100 10100 10100 10100 10100 10100 10100
				10100 10100 10100 10100 10100 10100 10100 10100 10100 10100 10100 10100 10100 10100 10100 10100 10100 10100
				10100 10100 10100 10100 10100 10100 10100 10100 10100 10100 10100 10100 10100 10100 10100 10100 10100 10100
				10100 10100 10100 10100 10100 10100 10100 10100 10100 10100 10100 10100 10100 10100 10100 10100 10100 10100
				10100 10100 10100 10100 10100 10100 10100 10100 10100 10100 10100 10100 10100 10100 10100 10100 10100 10100
				10100 10100 10100 10100 10100 10100 10100 10100 10100 10100 10100 10100 10100 10100 10100 10100 10100 10100
				10100 10100 10100 10100 10100 10100 10100 10100 10100 10100 10100 10100 10100 10100 10100 10100 10100 10100
				10100 10100 10100 10100 10100 10100 10100 10100 10100 10100 10100 10100 10100 10100 10100 10100 10100 10100
				10100 10100 10100 10100 10100 10100 10100 10100 10100 10100 10100 10100 10100 10100 10100 10100 10100 10100
				10100 10100 10100 10100 10100 10100 10100 10100 10100 10100 10100 10100 10100 10100 10100 10100 10100 10100
				10100 10100 10100 10100 10100 10100 10100 10100 10100 10100 10100 10100 10100 10100 10100 10100 10100 10100
				10100 10100 10100 10100 10100 10100 10100 10100 10100 10100 10100 10100 10100 10100 10100 10100 10100 10100
				10100 10100 10100 10100 10100 10100 10100 10100 10100 10100 10100 10100 10100 10100 10100 10100 10100 10100
				10100 10100 10100 10100 10100 10100 10100 10100 10100 10100 10100 10100 10100 10100 10100 10100 10100 10100
				10100 10100 10100 10100 10100 10100 10100 10100 10100 10100 10100 10100 10100 10100 10100 10100 10100 10100
				10100 10100 10100 10100 10100 10100 10100 10100 10100 10100 10100 10100 10100 10100 10100 10100 10100 10100
				10100 10100 10100 10100 10100 10100 10100 10100 10100 10100 10100 10100 10100 10100 10100 10100 10100 10100
				10100 10100 10100 10100 10100 10100 10100 10100 10100 10100 10100 10100 10100 10100 10100 10100 10100 10100
				10100 10100 10100 10100 10100 10100 10100 10100 10100 10100 10100 10100 10100 10100 10100 10100 10100 10100
				10100 10100 10100 10100 10100 10100 10100 10100 10100 10100 10100 10100 10100 10100 10100 10100 10100 10100
				10100 10100 10100 10100 10100 10100 10100 10100 10100 10100 10100 10100 10100 10100 10100 10100 10100 10100
				10100 10100 10100 10100 10100 10100 10100 10100 10100 10100 10100 10100 10100 10100 10100 10100 10100 10100
				10100 10100 10100 10100 10100 10100 10100 10100 10100 10100 10100 10100 10100 10100 10100 10100 10100 10100
				10100 10100 10100 10100 10100 10100 10100 10100 10100 10100 10100 10100 10100 10100 10100 10100 10100 10100
				10100 10100 10100 10100 10100 10100 10100 10100 10100 10100 10100 10100 10100 10100 10100 10100 10100 10100
				10000 10000 10000>;

			PS_Config_Lmt_Open_Rawdata_P = <
				3129 3173 3308 3414 3473 3535 3617 3662 3624 3582 3628 3582 3521 3490 3451 3362 3276 3259
				3200 3220 3351 3463 3530 3581 3663 3711 3676 3631 3672 3624 3571 3543 3500 3400 3299 3252
				3182 3221 3347 3486 3556 3623 3704 3764 3724 3691 3728 3682 3623 3598 3550 3446 3346 3333
				3201 3239 3367 3491 3556 3614 3687 3732 3803 3750 3710 3665 3617 3599 3561 3459 3365 3330
				3249 3266 3397 3529 3603 3659 3742 3791 3866 3872 3770 3731 3690 3659 3620 3508 3424 3402
				3333 3309 3444 3572 3652 3700 3787 3829 3897 3873 3785 3733 3694 3661 3614 3507 3407 3365
				3319 3316 3455 3572 3645 3703 3784 3827 3893 3935 3829 3788 3750 3715 3670 3574 3481 3459
				3372 3299 3453 3575 3656 3705 3785 3830 3903 3948 3829 3808 3773 3733 3676 3586 3487 3445
				3385 3402 3507 3634 3718 3770 3851 3906 3974 3983 3875 3815 3773 3745 3676 3586 3497 3466
				3463 3438 3526 3647 3729 3771 3844 3890 3948 4051 3959 3894 3850 3826 3750 3656 3564 3515
				3462 3470 3539 3696 3799 3841 3922 3964 4029 4089 3990 3879 3879 3857 3791 3694 3616 3570
				3515 3491 3592 3697 3796 3834 3914 3957 4015 4092 4019 3949 3897 3868 3796 3696 3613 3550
				3501 3514 3620 3717 3823 3878 3950 4002 4060 4097 4016 3963 3913 3885 3803 3710 3624 3581
				3561 3539 3630 3714 3833 3880 3946 3998 4058 4139 4069 4012 3950 3917 3822 3735 3637 3577
				3535 3553 3644 3721 3866 3917 3992 4046 4104 4144 4061 4013 3920 3917 3829 3739 3661 3607
				3578 3561 3642 3745 3850 3894 3966 4018 4078 4223 4160 4103 4037 3985 3886 3788 3696 3624
				3585 3592 3690 3802 3915 3964 4039 4083 4149 4242 4176 4121 4062 4006 3908 3819 3747 3680
				3649 3620 3712 3819 3906 3967 4039 4083 4152 4263 4214 4155 4079 3991 3890 3788 3714 3638
				3644 3656 3707 3746 3753 3810 3880 3920 3959 3992 3927 3876 3816 3747 3721 3668 3641 3714
				3637 3642 3698 3750 3785 3829 3896 3943 4005 3974 3908 3850 3784 3728 3673 3616 3586 3627
				3689 3712 3764 3802 3830 3866 3920 3970 4016 4004 3950 3904 3845 3803 3757 3711 3684 3740
				3711 3718 3774 3816 3843 3841 3913 3957 4026 3995 3935 3894 3823 3778 3694 3673 3637 3665
				3694 3718 3778 3831 3872 3901 3945 3984 4041 4040 3985 3948 3883 3845 3791 3739 3712 3759
				3745 3759 3809 3864 3890 3914 3946 3994 4061 4040 3990 3953 3887 3851 3808 3736 3701 3714
				3672 3694 3756 3805 3837 3868 3906 3952 4011 4030 3983 3941 3880 3847 3803 3745 3711 3746
				3726 3742 3796 3841 3871 3894 3903 3970 4043 4102 4043 3998 3935 3885 3833 3743 3721 3722
				3680 3715 3764 3810 3834 3862 3893 3935 3999 4086 4032 3998 3934 3904 3862 3808 3750 3778
				3771 3794 3845 3892 3920 3945 3973 4006 4090 4110 4047 4011 3939 3897 3838 3777 3707 3710
				3714 3754 3812 3864 3897 3920 3959 3973 4058 4116 4055 4022 3959 3924 3878 3813 3729 3767
				3717 3736 3785 3834 3862 3885 3918 3950 4015 4085 4022 3983 3908 3871 3824 3760 3694 3673
				3733 3774 3854 3903 3935 3970 4002 4036 4095 4089 4032 3997 3931 3893 3848 3788 3718 3724
				3729 3735 3813 3864 3889 3910 3942 3973 4040 4135 4068 4029 3967 3924 3876 3816 3733 3717
				3733 3766 3848 3903 3932 3960 3997 4033 4075 4104 4047 4022 3963 3931 3894 3845 3760 3740
				3711 3831 3918 3978 4011 4034 4071 4103 4160 4279 4215 4176 4100 4057 4001 3935 3827 3679
				3540 3858 3967 4025 4057 4074 4127 4158 4208 4281 4208 4165 4096 4053 4004 3945 3847 3523
				3409 3806 3970 4033 4074 4102 4153 4186 4244 4317 4249 4200 4128 4081 4029 3949 3778 3329
				5120 5120 5120>;

			PS_Config_Lmt_Open_Rawdata_N = <
				1341 1360 1417 1463 1488 1515 1550 1569 1553 1535 1555 1535 1509 1495 1479 1441 1404 1396
				1371 1380 1436 1484 1513 1534 1570 1590 1575 1556 1573 1553 1530 1518 1500 1457 1414 1393
				1363 1380 1434 1494 1524 1552 1587 1613 1596 1582 1597 1578 1552 1542 1521 1477 1434 1428
				1372 1388 1443 1496 1524 1549 1580 1599 1630 1607 1590 1570 1550 1542 1526 1482 1442 1427
				1392 1399 1456 1512 1544 1568 1603 1624 1657 1659 1615 1599 1581 1568 1551 1503 1467 1458
				1428 1418 1476 1531 1565 1585 1623 1641 1670 1660 1622 1600 1583 1569 1549 1503 1460 1442
				1422 1421 1480 1531 1562 1587 1621 1640 1668 1686 1641 1623 1607 1592 1573 1531 1492 1482
				1445 1414 1480 1532 1567 1588 1622 1641 1672 1692 1641 1632 1617 1600 1575 1537 1494 1476
				1450 1458 1503 1557 1593 1615 1650 1674 1703 1707 1660 1635 1617 1605 1575 1537 1498 1485
				1484 1473 1511 1563 1598 1616 1647 1667 1692 1736 1696 1669 1650 1639 1607 1567 1527 1506
				1483 1487 1516 1584 1628 1646 1681 1699 1726 1752 1710 1662 1662 1653 1624 1583 1549 1530
				1506 1496 1539 1584 1627 1643 1677 1696 1720 1753 1722 1692 1670 1657 1627 1584 1548 1521
				1500 1506 1551 1593 1638 1662 1693 1715 1740 1756 1721 1698 1677 1665 1630 1590 1553 1534
				1526 1516 1555 1591 1642 1663 1691 1713 1739 1774 1744 1719 1693 1678 1638 1600 1558 1533
				1515 1522 1561 1594 1657 1678 1711 1734 1759 1776 1740 1720 1680 1678 1641 1602 1569 1546
				1533 1526 1561 1605 1650 1669 1699 1722 1747 1810 1783 1758 1730 1708 1665 1623 1584 1553
				1536 1539 1581 1629 1678 1699 1731 1750 1778 1818 1789 1766 1741 1717 1675 1636 1606 1577
				1564 1551 1591 1636 1674 1700 1731 1750 1779 1827 1806 1780 1748 1710 1667 1623 1591 1559
				1561 1567 1588 1605 1608 1633 1663 1680 1696 1711 1683 1661 1635 1606 1594 1572 1560 1591
				1558 1561 1585 1607 1622 1641 1669 1690 1716 1703 1675 1650 1621 1597 1574 1549 1537 1554
				1581 1591 1613 1629 1641 1657 1680 1701 1721 1716 1693 1673 1648 1630 1610 1590 1579 1603
				1590 1593 1617 1635 1647 1646 1677 1696 1725 1712 1686 1669 1638 1619 1583 1574 1558 1570
				1583 1593 1619 1642 1659 1672 1690 1707 1732 1731 1708 1692 1664 1648 1624 1602 1591 1611
				1605 1611 1632 1656 1667 1677 1691 1711 1740 1731 1710 1694 1666 1650 1632 1601 1586 1591
				1573 1583 1609 1630 1644 1657 1674 1693 1719 1727 1707 1689 1663 1648 1630 1605 1590 1605
				1597 1603 1627 1646 1659 1669 1672 1701 1732 1758 1732 1713 1686 1665 1642 1604 1594 1595
				1577 1592 1613 1633 1643 1655 1668 1686 1714 1751 1728 1713 1686 1673 1655 1632 1607 1619
				1616 1626 1648 1668 1680 1690 1702 1717 1753 1761 1734 1719 1688 1670 1645 1618 1588 1590
				1591 1609 1633 1656 1670 1680 1696 1702 1739 1764 1738 1723 1696 1681 1662 1634 1598 1614
				1593 1601 1622 1643 1655 1665 1679 1693 1720 1750 1723 1707 1675 1659 1639 1611 1583 1574
				1600 1617 1651 1672 1686 1701 1715 1729 1755 1752 1728 1713 1684 1668 1649 1623 1593 1596
				1598 1600 1634 1656 1666 1675 1689 1702 1731 1772 1743 1726 1700 1681 1661 1635 1600 1593
				1600 1614 1649 1672 1685 1697 1713 1728 1746 1759 1734 1723 1698 1684 1669 1648 1611 1603
				1590 1642 1679 1705 1719 1729 1744 1758 1783 1834 1806 1789 1757 1738 1714 1686 1640 1576
				1517 1653 1700 1725 1738 1746 1768 1782 1803 1834 1803 1785 1755 1737 1716 1690 1648 1510
				1461 1631 1701 1728 1746 1758 1780 1794 1819 1850 1821 1800 1769 1749 1726 1692 1619 1426
				(-511) (-511) (-511)>;

			PS_Config_Lmt_FW_Rawdata_P = <
				1103 1101 1097 1107 1097 1118 1121 1132 1093 1111 1113 1118 1120 1113 1114 1101 1114 1110
				1104 1115 1113 1094 1113 1099 1103 1128 1114 1111 1111 1110 1107 1101 1101 1111 1118 1117
				1120 1079 1086 1101 1083 1103 1101 1117 1092 1107 1093 1110 1103 1104 1106 1111 1117 1113
				1114 1096 1114 1113 1101 1117 1120 1099 1086 1118 1124 1129 1121 1131 1117 1114 1113 1099
				1114 1114 1115 1114 1117 1125 1124 1120 1129 1113 1113 1122 1124 1089 1125 1128 1122 1092
				1115 1101 1085 1097 1092 1118 1120 1118 1104 1111 1101 1096 1100 1096 1099 1097 1097 1135
				1110 1129 1127 1127 1127 1128 1129 1122 1114 1118 1096 1094 1104 1106 1104 1103 1100 1108
				1107 1121 1114 1107 1101 1114 1115 1128 1118 1093 1121 1118 1122 1136 1129 1127 1127 1107
				1097 1115 1118 1110 1106 1094 1101 1093 1096 1129 1118 1120 1107 1104 1100 1097 1104 1115
				1132 1127 1132 1141 1141 1124 1135 1103 1117 1111 1114 1118 1103 1103 1107 1111 1121 1093
				1115 1125 1125 1121 1124 1114 1113 1099 1115 1106 1104 1101 1122 1118 1115 1124 1117 1101
				1101 1125 1117 1113 1110 1099 1093 1135 1128 1132 1104 1103 1097 1101 1110 1110 1107 1125
				1107 1115 1110 1114 1120 1108 1107 1118 1106 1108 1115 1120 1131 1132 1132 1124 1122 1101
				1129 1097 1097 1117 1103 1148 1143 1099 1106 1108 1129 1129 1108 1092 1099 1100 1108 1139
				1108 1121 1125 1110 1125 1096 1099 1099 1107 1111 1114 1117 1108 1113 1108 1110 1103 1111
				1117 1096 1114 1124 1120 1099 1106 1124 1115 1129 1111 1121 1106 1093 1100 1108 1107 1115
				1111 1097 1104 1110 1115 1121 1122 1121 1106 1092 1124 1110 1090 1136 1138 1127 1118 1097
				1120 1108 1125 1122 1121 1111 1110 1118 1113 1120 1113 1111 1113 1108 1127 1122 1125 1093
				1139 1110 1117 1114 1107 1096 1099 1110 1106 1129 1131 1131 1124 1113 1110 1106 1093 1139
				1115 1115 1110 1115 1118 1114 1118 1120 1108 1107 1111 1110 1107 1099 1104 1106 1118 1120
				1134 1096 1099 1108 1096 1115 1117 1114 1125 1118 1104 1106 1111 1120 1113 1124 1108 1115
				1107 1111 1114 1122 1118 1114 1125 1129 1118 1093 1117 1110 1108 1121 1113 1122 1127 1099
				1104 1117 1121 1124 1120 1121 1100 1099 1097 1115 1107 1127 1124 1117 1117 1111 1113 1107
				1121 1114 1114 1106 1111 1103 1111 1111 1092 1104 1128 1103 1107 1114 1104 1104 1115 1120
				1127 1099 1103 1108 1103 1097 1111 1110 1127 1120 1121 1118 1117 1110 1115 1110 1108 1128
				1120 1125 1128 1131 1121 1118 1122 1128 1110 1108 1115 1104 1111 1103 1103 1101 1106 1111
				1122 1107 1110 1107 1106 1108 1101 1096 1118 1083 1127 1127 1125 1120 1122 1122 1108 1113
				1075 1103 1106 1100 1108 1110 1135 1152 1071 1113 1121 1108 1110 1117 1111 1114 1111 1110
				1114 1125 1114 1122 1093 1108 1100 1090 1113 1100 1118 1111 1118 1117 1117 1111 1114 1120
				1113 1117 1125 1115 1127 1127 1134 1127 1106 1107 1103 1124 1114 1138 1128 1120 1122 1108
				1124 1115 1129 1120 1124 1124 1129 1125 1108 1135 1117 1134 1115 1117 1115 1115 1107 1092
				1132 1104 1090 1110 1106 1100 1094 1090 1120 1103 1108 1090 1111 1099 1107 1099 1125 1128
				1139 1089 1100 1094 1122 1092 1115 1103 1122 1128 1124 1125 1122 1121 1118 1124 1106 1107
				1113 1122 1136 1135 1138 1143 1135 1139 1135 1106 1100 1114 1121 1121 1117 1124 1120 1101
				1106 1110 1124 1114 1131 1125 1114 1129 1104 1141 1076 1080 1089 1096 1110 1080 1125 1085
				1114 1121 1139 1127 1121 1141 1107 1099 1124 1143 1118 1092 1108 1094 1113 1110 1124 1114
				2560 2560 2560>;

			PS_Config_Lmt_FW_Rawdata_N = <
				472 472 470 474 470 479 480 485 468 476 477 479 480 477 477 472 477 475
				473 478 477 469 477 471 472 483 477 476 476 475 474 472 472 476 479 478
				480 462 465 472 464 472 472 478 468 474 468 475 472 473 474 476 478 477
				477 469 477 477 472 478 480 471 465 479 481 484 480 484 478 477 477 471
				477 477 478 477 478 482 481 480 484 477 477 481 481 466 482 483 481 468
				478 472 465 470 468 479 480 479 473 476 472 469 471 469 471 470 470 486
				475 484 483 483 483 483 484 481 477 479 469 469 473 474 473 472 471 475
				474 480 477 474 472 477 478 483 479 468 480 479 481 487 484 483 483 474
				470 478 479 475 474 469 472 468 469 484 479 480 474 473 471 470 473 478
				485 483 485 489 489 481 486 472 478 476 477 479 472 472 474 476 480 468
				478 482 482 480 481 477 477 471 478 474 473 472 481 479 478 481 478 472
				472 482 478 477 475 471 468 486 483 485 473 472 470 472 475 475 474 482
				474 478 475 477 480 475 474 479 474 475 478 480 484 485 485 481 481 472
				484 470 470 478 472 492 490 471 474 475 484 484 475 468 471 471 475 488
				475 480 482 475 482 469 471 471 474 476 477 478 475 477 475 475 472 476
				478 469 477 481 480 471 474 481 478 484 476 480 474 468 471 475 474 478
				476 470 473 475 478 480 481 480 474 468 481 475 467 487 487 483 479 470
				480 475 482 481 480 476 475 479 477 480 477 476 477 475 483 481 482 468
				488 475 478 477 474 469 471 475 474 484 484 484 481 477 475 474 468 488
				478 478 475 478 479 477 479 480 475 474 476 475 474 471 473 474 479 480
				486 469 471 475 469 478 478 477 482 479 473 474 476 480 477 481 475 478
				474 476 477 481 479 477 482 484 479 468 478 475 475 480 477 481 483 471
				473 478 480 481 480 480 471 471 470 478 474 483 481 478 478 476 477 474
				480 477 477 474 476 472 476 476 468 473 483 472 474 477 473 473 478 480
				483 471 472 475 472 470 476 475 483 480 480 479 478 475 478 475 475 483
				480 482 483 484 480 479 481 483 475 475 478 473 476 472 472 472 474 476
				481 474 475 474 474 475 472 469 479 464 483 483 482 480 481 481 475 477
				460 472 474 471 475 475 486 493 459 477 480 475 475 478 476 477 476 475
				477 482 477 481 468 475 471 467 477 471 479 476 479 478 478 476 477 480
				477 478 482 478 483 483 486 483 474 474 472 481 477 487 483 480 481 475
				481 478 484 480 481 481 484 482 475 486 478 486 478 478 478 478 474 468
				485 473 467 475 474 471 469 467 480 472 475 467 476 471 474 471 482 483
				488 466 471 469 481 468 478 472 481 483 481 482 481 480 479 481 474 474
				477 481 487 486 487 490 486 488 486 474 471 477 480 480 478 481 480 472
				474 475 481 477 484 482 477 484 473 489 461 463 466 469 475 463 482 465
				477 480 488 483 480 489 474 471 481 490 479 468 475 469 477 475 481 477
				240 240 240>;

			PS_Config_Lmt_FW_CC_P = <
				53 53 53 53 53 53 53 53 56 56 55 55 55 53 55 55 53 53
				53 53 53 53 53 53 53 53 56 55 53 53 53 53 53 53 53 53
				53 53 53 53 53 53 53 53 56 55 53 53 53 53 53 53 53 53
				53 53 53 53 53 53 53 55 56 55 53 53 53 53 53 53 53 53
				53 53 53 53 53 53 53 53 55 55 53 53 53 53 53 53 53 53
				55 53 53 53 53 53 53 55 56 55 53 53 53 53 53 53 53 53
				53 53 53 53 53 53 53 53 55 55 53 53 53 53 53 53 53 53
				55 53 53 53 53 53 53 55 56 55 53 53 53 53 53 53 53 55
				53 53 53 53 53 53 53 53 55 55 53 53 53 53 53 53 53 53
				55 53 53 53 53 55 55 55 56 56 53 53 53 53 53 53 53 55
				53 53 53 53 53 53 53 55 55 56 53 53 53 53 53 53 53 53
				53 53 53 53 53 53 53 55 56 56 55 53 53 53 53 53 53 55
				53 53 53 53 53 53 53 53 55 55 55 55 53 53 53 53 53 55
				55 53 55 55 55 55 55 56 57 55 53 55 53 53 53 53 53 55
				53 53 53 53 53 53 53 53 56 55 55 55 53 53 53 53 53 55
				55 53 53 53 53 55 55 55 57 55 53 53 53 53 53 53 53 55
				53 53 53 53 53 55 55 55 56 55 55 55 55 53 53 53 53 55
				55 53 53 55 55 55 55 55 57 55 53 53 53 53 53 53 53 55
				55 53 53 53 53 53 53 53 53 57 55 55 55 53 53 53 53 55
				55 53 53 53 53 55 55 53 55 57 55 55 53 53 53 53 53 55
				53 53 53 53 53 53 53 53 53 56 55 53 53 53 53 53 53 55
				55 53 53 53 53 53 53 53 55 57 55 55 55 53 53 53 53 55
				55 53 53 53 53 53 53 53 55 56 55 55 55 53 55 53 53 55
				55 53 53 53 53 53 55 55 56 56 55 55 55 53 53 53 53 55
				53 53 53 53 53 53 53 53 55 56 53 53 53 53 53 53 53 55
				55 53 53 53 53 53 55 55 56 56 55 53 53 53 53 53 53 55
				55 53 53 53 53 53 53 55 56 56 53 53 53 53 53 53 53 55
				55 53 55 55 55 55 55 55 56 56 55 53 53 53 53 53 53 55
				53 53 53 53 53 53 53 53 55 56 53 53 53 53 53 53 53 55
				55 53 53 53 53 53 53 55 56 56 55 53 53 53 53 53 53 55
				53 53 53 53 53 53 53 53 55 56 53 53 53 53 53 53 53 55
				55 53 53 53 55 53 55 55 56 56 55 53 53 53 53 53 53 55
				53 53 53 53 53 53 53 53 56 56 53 53 53 53 53 53 53 55
				55 53 55 55 55 55 55 55 57 56 55 53 53 53 53 53 53 55
				53 53 53 53 53 53 53 53 56 56 55 55 53 53 53 53 53 53
				53 55 55 55 55 55 55 55 57 56 55 55 55 55 53 53 53 53
				314 314 314>;

			PS_Config_Lmt_FW_CC_N = <
				24 24 24 24 24 24 24 24 25 25 24 24 24 24 24 24 24 24
				24 24 24 24 24 24 24 24 25 24 24 24 24 24 24 24 24 24
				24 24 24 24 24 24 24 24 25 24 24 24 24 24 24 24 24 24
				24 24 24 24 24 24 24 24 25 24 24 24 24 24 24 24 24 24
				24 24 24 24 24 24 24 24 24 24 24 24 24 24 24 24 24 24
				24 24 24 24 24 24 24 24 25 24 24 24 24 24 24 24 24 24
				24 24 24 24 24 24 24 24 24 24 24 24 24 24 24 24 24 24
				24 24 24 24 24 24 24 24 25 24 24 24 24 24 24 24 24 24
				24 24 24 24 24 24 24 24 24 24 24 24 24 24 24 24 24 24
				24 24 24 24 24 24 24 24 25 25 24 24 24 24 24 24 24 24
				24 24 24 24 24 24 24 24 24 25 24 24 24 24 24 24 24 24
				24 24 24 24 24 24 24 24 25 25 24 24 24 24 24 24 24 24
				24 24 24 24 24 24 24 24 24 24 24 24 24 24 24 24 24 24
				24 24 24 24 24 24 24 25 26 24 24 24 24 24 24 24 24 24
				24 24 24 24 24 24 24 24 25 24 24 24 24 24 24 24 24 24
				24 24 24 24 24 24 24 24 26 24 24 24 24 24 24 24 24 24
				24 24 24 24 24 24 24 24 25 24 24 24 24 24 24 24 24 24
				24 24 24 24 24 24 24 24 26 24 24 24 24 24 24 24 24 24
				24 24 24 24 24 24 24 24 24 26 24 24 24 24 24 24 24 24
				24 24 24 24 24 24 24 24 24 26 24 24 24 24 24 24 24 24
				24 24 24 24 24 24 24 24 24 25 24 24 24 24 24 24 24 24
				24 24 24 24 24 24 24 24 24 26 24 24 24 24 24 24 24 24
				24 24 24 24 24 24 24 24 24 25 24 24 24 24 24 24 24 24
				24 24 24 24 24 24 24 24 25 25 24 24 24 24 24 24 24 24
				24 24 24 24 24 24 24 24 24 25 24 24 24 24 24 24 24 24
				24 24 24 24 24 24 24 24 25 25 24 24 24 24 24 24 24 24
				24 24 24 24 24 24 24 24 25 25 24 24 24 24 24 24 24 24
				24 24 24 24 24 24 24 24 25 25 24 24 24 24 24 24 24 24
				24 24 24 24 24 24 24 24 24 25 24 24 24 24 24 24 24 24
				24 24 24 24 24 24 24 24 25 25 24 24 24 24 24 24 24 24
				24 24 24 24 24 24 24 24 24 25 24 24 24 24 24 24 24 24
				24 24 24 24 24 24 24 24 25 25 24 24 24 24 24 24 24 24
				24 24 24 24 24 24 24 24 25 25 24 24 24 24 24 24 24 24
				24 24 24 24 24 24 24 24 26 25 24 24 24 24 24 24 24 24
				24 24 24 24 24 24 24 24 25 25 24 24 24 24 24 24 24 24
				24 24 24 24 24 24 24 24 26 25 24 24 24 24 24 24 24 24
				0 0 0>;

			PS_Config_Lmt_FW_Diff_P = <
				50 50 50 50 50 50 50 50 50 50 50 50 50 50 50 50 50 50
				50 50 50 50 50 50 50 50 50 50 50 50 50 50 50 50 50 50
				50 50 50 50 50 50 50 50 50 50 50 50 50 50 50 50 50 50
				50 50 50 50 50 50 50 50 50 50 50 50 50 50 50 50 50 50
				50 50 50 50 50 50 50 50 50 50 50 50 50 50 50 50 50 50
				50 50 50 50 50 50 50 50 50 50 50 50 50 50 50 50 50 50
				50 50 50 50 50 50 50 50 50 50 50 50 50 50 50 50 50 50
				50 50 50 50 50 50 50 50 50 50 50 50 50 50 50 50 50 50
				50 50 50 50 50 50 50 50 50 50 50 50 50 50 50 50 50 50
				50 50 50 50 50 50 50 50 50 50 50 50 50 50 50 50 50 50
				50 50 50 50 50 50 50 50 50 50 50 50 50 50 50 50 50 50
				50 50 50 50 50 50 50 50 50 50 50 50 50 50 50 50 50 50
				50 50 50 50 50 50 50 50 50 50 50 50 50 50 50 50 50 50
				50 50 50 50 50 50 50 50 50 50 50 50 50 50 50 50 50 50
				50 50 50 50 50 50 50 50 50 50 50 50 50 50 50 50 50 50
				50 50 50 50 50 50 50 50 50 50 50 50 50 50 50 50 50 50
				50 50 50 50 50 50 50 50 50 50 50 50 50 50 50 50 50 50
				50 50 50 50 50 50 50 50 50 50 50 50 50 50 50 50 50 50
				50 50 50 50 50 50 50 50 50 50 50 50 50 50 50 50 50 50
				50 50 50 50 50 50 50 50 50 50 50 50 50 50 50 50 50 50
				50 50 50 50 50 50 50 50 50 50 50 50 50 50 50 50 50 50
				50 50 50 50 50 50 50 50 50 50 50 50 50 50 50 50 50 50
				50 50 50 50 50 50 50 50 50 50 50 50 50 50 50 50 50 50
				50 50 50 50 50 50 50 50 50 50 50 50 50 50 50 50 50 50
				50 50 50 50 50 50 50 50 50 50 50 50 50 50 50 50 50 50
				50 50 50 50 50 50 50 50 50 50 50 50 50 50 50 50 50 50
				50 50 50 50 50 50 50 50 50 50 50 50 50 50 50 50 50 50
				50 50 50 50 50 50 50 50 50 50 50 50 50 50 50 50 50 50
				50 50 50 50 50 50 50 50 50 50 50 50 50 50 50 50 50 50
				50 50 50 50 50 50 50 50 50 50 50 50 50 50 50 50 50 50
				50 50 50 50 50 50 50 50 50 50 50 50 50 50 50 50 50 50
				50 50 50 50 50 50 50 50 50 50 50 50 50 50 50 50 50 50
				50 50 50 50 50 50 50 50 50 50 50 50 50 50 50 50 50 50
				50 50 50 50 50 50 50 50 50 50 50 50 50 50 50 50 50 50
				50 50 50 50 50 50 50 50 50 50 50 50 50 50 50 50 50 50
				50 50 50 50 50 50 50 50 50 50 50 50 50 50 50 50 50 50
				75 75 75>;

			PS_Config_Lmt_FW_Diff_N = <
				(-50) (-50) (-50) (-50) (-50) (-50) (-50) (-50) (-50) (-50) (-50) (-50) (-50) (-50) (-50) (-50) (-50) (-50)
				(-50) (-50) (-50) (-50) (-50) (-50) (-50) (-50) (-50) (-50) (-50) (-50) (-50) (-50) (-50) (-50) (-50) (-50)
				(-50) (-50) (-50) (-50) (-50) (-50) (-50) (-50) (-50) (-50) (-50) (-50) (-50) (-50) (-50) (-50) (-50) (-50)
				(-50) (-50) (-50) (-50) (-50) (-50) (-50) (-50) (-50) (-50) (-50) (-50) (-50) (-50) (-50) (-50) (-50) (-50)
				(-50) (-50) (-50) (-50) (-50) (-50) (-50) (-50) (-50) (-50) (-50) (-50) (-50) (-50) (-50) (-50) (-50) (-50)
				(-50) (-50) (-50) (-50) (-50) (-50) (-50) (-50) (-50) (-50) (-50) (-50) (-50) (-50) (-50) (-50) (-50) (-50)
				(-50) (-50) (-50) (-50) (-50) (-50) (-50) (-50) (-50) (-50) (-50) (-50) (-50) (-50) (-50) (-50) (-50) (-50)
				(-50) (-50) (-50) (-50) (-50) (-50) (-50) (-50) (-50) (-50) (-50) (-50) (-50) (-50) (-50) (-50) (-50) (-50)
				(-50) (-50) (-50) (-50) (-50) (-50) (-50) (-50) (-50) (-50) (-50) (-50) (-50) (-50) (-50) (-50) (-50) (-50)
				(-50) (-50) (-50) (-50) (-50) (-50) (-50) (-50) (-50) (-50) (-50) (-50) (-50) (-50) (-50) (-50) (-50) (-50)
				(-50) (-50) (-50) (-50) (-50) (-50) (-50) (-50) (-50) (-50) (-50) (-50) (-50) (-50) (-50) (-50) (-50) (-50)
				(-50) (-50) (-50) (-50) (-50) (-50) (-50) (-50) (-50) (-50) (-50) (-50) (-50) (-50) (-50) (-50) (-50) (-50)
				(-50) (-50) (-50) (-50) (-50) (-50) (-50) (-50) (-50) (-50) (-50) (-50) (-50) (-50) (-50) (-50) (-50) (-50)
				(-50) (-50) (-50) (-50) (-50) (-50) (-50) (-50) (-50) (-50) (-50) (-50) (-50) (-50) (-50) (-50) (-50) (-50)
				(-50) (-50) (-50) (-50) (-50) (-50) (-50) (-50) (-50) (-50) (-50) (-50) (-50) (-50) (-50) (-50) (-50) (-50)
				(-50) (-50) (-50) (-50) (-50) (-50) (-50) (-50) (-50) (-50) (-50) (-50) (-50) (-50) (-50) (-50) (-50) (-50)
				(-50) (-50) (-50) (-50) (-50) (-50) (-50) (-50) (-50) (-50) (-50) (-50) (-50) (-50) (-50) (-50) (-50) (-50)
				(-50) (-50) (-50) (-50) (-50) (-50) (-50) (-50) (-50) (-50) (-50) (-50) (-50) (-50) (-50) (-50) (-50) (-50)
				(-50) (-50) (-50) (-50) (-50) (-50) (-50) (-50) (-50) (-50) (-50) (-50) (-50) (-50) (-50) (-50) (-50) (-50)
				(-50) (-50) (-50) (-50) (-50) (-50) (-50) (-50) (-50) (-50) (-50) (-50) (-50) (-50) (-50) (-50) (-50) (-50)
				(-50) (-50) (-50) (-50) (-50) (-50) (-50) (-50) (-50) (-50) (-50) (-50) (-50) (-50) (-50) (-50) (-50) (-50)
				(-50) (-50) (-50) (-50) (-50) (-50) (-50) (-50) (-50) (-50) (-50) (-50) (-50) (-50) (-50) (-50) (-50) (-50)
				(-50) (-50) (-50) (-50) (-50) (-50) (-50) (-50) (-50) (-50) (-50) (-50) (-50) (-50) (-50) (-50) (-50) (-50)
				(-50) (-50) (-50) (-50) (-50) (-50) (-50) (-50) (-50) (-50) (-50) (-50) (-50) (-50) (-50) (-50) (-50) (-50)
				(-50) (-50) (-50) (-50) (-50) (-50) (-50) (-50) (-50) (-50) (-50) (-50) (-50) (-50) (-50) (-50) (-50) (-50)
				(-50) (-50) (-50) (-50) (-50) (-50) (-50) (-50) (-50) (-50) (-50) (-50) (-50) (-50) (-50) (-50) (-50) (-50)
				(-50) (-50) (-50) (-50) (-50) (-50) (-50) (-50) (-50) (-50) (-50) (-50) (-50) (-50) (-50) (-50) (-50) (-50)
				(-50) (-50) (-50) (-50) (-50) (-50) (-50) (-50) (-50) (-50) (-50) (-50) (-50) (-50) (-50) (-50) (-50) (-50)
				(-50) (-50) (-50) (-50) (-50) (-50) (-50) (-50) (-50) (-50) (-50) (-50) (-50) (-50) (-50) (-50) (-50) (-50)
				(-50) (-50) (-50) (-50) (-50) (-50) (-50) (-50) (-50) (-50) (-50) (-50) (-50) (-50) (-50) (-50) (-50) (-50)
				(-50) (-50) (-50) (-50) (-50) (-50) (-50) (-50) (-50) (-50) (-50) (-50) (-50) (-50) (-50) (-50) (-50) (-50)
				(-50) (-50) (-50) (-50) (-50) (-50) (-50) (-50) (-50) (-50) (-50) (-50) (-50) (-50) (-50) (-50) (-50) (-50)
				(-50) (-50) (-50) (-50) (-50) (-50) (-50) (-50) (-50) (-50) (-50) (-50) (-50) (-50) (-50) (-50) (-50) (-50)
				(-50) (-50) (-50) (-50) (-50) (-50) (-50) (-50) (-50) (-50) (-50) (-50) (-50) (-50) (-50) (-50) (-50) (-50)
				(-50) (-50) (-50) (-50) (-50) (-50) (-50) (-50) (-50) (-50) (-50) (-50) (-50) (-50) (-50) (-50) (-50) (-50)
				(-50) (-50) (-50) (-50) (-50) (-50) (-50) (-50) (-50) (-50) (-50) (-50) (-50) (-50) (-50) (-50) (-50) (-50)
				(-75) (-75) (-75)>;

			PS_Config_Diff_Test_Frame = <50>;
		};/*36672C tm Module*/

		/*36672D tm Module*/
		novatek-mp-criteria-594C@0 {
			#address-cells = <1>;
			#size-cells = <0>;
			compatible = "novatek-mp-criteria-594C";

			/* MP Config */
			IC_X_CFG_SIZE = <18>;
			IC_Y_CFG_SIZE = <36>;
			IC_KEY_CFG_SIZE = <4>;
			X_Channel = <18>;
			Y_Channel = <36>;
			AIN_X = <0 1 2 3 4 5 6 7 8 9 10 11 12 13 14 15 16 17>;
			AIN_Y = <0 1 2 3 4 5 6 7 8 9 10 11 12 13 14 15 16 17
						18 19 20 21 22 23 24 25 26 27 28 29 30 31 32 33 34 35>;
			AIN_KEY = <0 1 2 0xFF>;

			/* MP Criteria */
			PS_Config_Lmt_Short_Rawdata_P = <
				14008 14008 14008 14008 14008 14008 14008 14008 14008 14008 14008 14008 14008 14008 14008 14008 14008 14008
				14008 14008 14008 14008 14008 14008 14008 14008 14008 14008 14008 14008 14008 14008 14008 14008 14008 14008
				14008 14008 14008 14008 14008 14008 14008 14008 14008 14008 14008 14008 14008 14008 14008 14008 14008 14008
				14008 14008 14008 14008 14008 14008 14008 14008 14008 14008 14008 14008 14008 14008 14008 14008 14008 14008
				14008 14008 14008 14008 14008 14008 14008 14008 14008 14008 14008 14008 14008 14008 14008 14008 14008 14008
				14008 14008 14008 14008 14008 14008 14008 14008 14008 14008 14008 14008 14008 14008 14008 14008 14008 14008
				14008 14008 14008 14008 14008 14008 14008 14008 14008 14008 14008 14008 14008 14008 14008 14008 14008 14008
				14008 14008 14008 14008 14008 14008 14008 14008 14008 14008 14008 14008 14008 14008 14008 14008 14008 14008
				14008 14008 14008 14008 14008 14008 14008 14008 14008 14008 14008 14008 14008 14008 14008 14008 14008 14008
				14008 14008 14008 14008 14008 14008 14008 14008 14008 14008 14008 14008 14008 14008 14008 14008 14008 14008
				14008 14008 14008 14008 14008 14008 14008 14008 14008 14008 14008 14008 14008 14008 14008 14008 14008 14008
				14008 14008 14008 14008 14008 14008 14008 14008 14008 14008 14008 14008 14008 14008 14008 14008 14008 14008
				14008 14008 14008 14008 14008 14008 14008 14008 14008 14008 14008 14008 14008 14008 14008 14008 14008 14008
				14008 14008 14008 14008 14008 14008 14008 14008 14008 14008 14008 14008 14008 14008 14008 14008 14008 14008
				14008 14008 14008 14008 14008 14008 14008 14008 14008 14008 14008 14008 14008 14008 14008 14008 14008 14008
				14008 14008 14008 14008 14008 14008 14008 14008 14008 14008 14008 14008 14008 14008 14008 14008 14008 14008
				14008 14008 14008 14008 14008 14008 14008 14008 14008 14008 14008 14008 14008 14008 14008 14008 14008 14008
				14008 14008 14008 14008 14008 14008 14008 14008 14008 14008 14008 14008 14008 14008 14008 14008 14008 14008
				14008 14008 14008 14008 14008 14008 14008 14008 14008 14008 14008 14008 14008 14008 14008 14008 14008 14008
				14008 14008 14008 14008 14008 14008 14008 14008 14008 14008 14008 14008 14008 14008 14008 14008 14008 14008
				14008 14008 14008 14008 14008 14008 14008 14008 14008 14008 14008 14008 14008 14008 14008 14008 14008 14008
				14008 14008 14008 14008 14008 14008 14008 14008 14008 14008 14008 14008 14008 14008 14008 14008 14008 14008
				14008 14008 14008 14008 14008 14008 14008 14008 14008 14008 14008 14008 14008 14008 14008 14008 14008 14008
				14008 14008 14008 14008 14008 14008 14008 14008 14008 14008 14008 14008 14008 14008 14008 14008 14008 14008
				14008 14008 14008 14008 14008 14008 14008 14008 14008 14008 14008 14008 14008 14008 14008 14008 14008 14008
				14008 14008 14008 14008 14008 14008 14008 14008 14008 14008 14008 14008 14008 14008 14008 14008 14008 14008
				14008 14008 14008 14008 14008 14008 14008 14008 14008 14008 14008 14008 14008 14008 14008 14008 14008 14008
				14008 14008 14008 14008 14008 14008 14008 14008 14008 14008 14008 14008 14008 14008 14008 14008 14008 14008
				14008 14008 14008 14008 14008 14008 14008 14008 14008 14008 14008 14008 14008 14008 14008 14008 14008 14008
				14008 14008 14008 14008 14008 14008 14008 14008 14008 14008 14008 14008 14008 14008 14008 14008 14008 14008
				14008 14008 14008 14008 14008 14008 14008 14008 14008 14008 14008 14008 14008 14008 14008 14008 14008 14008
				14008 14008 14008 14008 14008 14008 14008 14008 14008 14008 14008 14008 14008 14008 14008 14008 14008 14008
				14008 14008 14008 14008 14008 14008 14008 14008 14008 14008 14008 14008 14008 14008 14008 14008 14008 14008
				14008 14008 14008 14008 14008 14008 14008 14008 14008 14008 14008 14008 14008 14008 14008 14008 14008 14008
				14008 14008 14008 14008 14008 14008 14008 14008 14008 14008 14008 14008 14008 14008 14008 14008 14008 14008
				14008 14008 14008 14008 14008 14008 14008 14008 14008 14008 14008 14008 14008 14008 14008 14008 14008 14008
				14008 14008 14008>;

			PS_Config_Lmt_Short_Rawdata_N = <
				10100 10100 10100 10100 10100 10100 10100 10100 10100 10100 10100 10100 10100 10100 10100 10100 10100 10100
				10100 10100 10100 10100 10100 10100 10100 10100 10100 10100 10100 10100 10100 10100 10100 10100 10100 10100
				10100 10100 10100 10100 10100 10100 10100 10100 10100 10100 10100 10100 10100 10100 10100 10100 10100 10100
				10100 10100 10100 10100 10100 10100 10100 10100 10100 10100 10100 10100 10100 10100 10100 10100 10100 10100
				10100 10100 10100 10100 10100 10100 10100 10100 10100 10100 10100 10100 10100 10100 10100 10100 10100 10100
				10100 10100 10100 10100 10100 10100 10100 10100 10100 10100 10100 10100 10100 10100 10100 10100 10100 10100
				10100 10100 10100 10100 10100 10100 10100 10100 10100 10100 10100 10100 10100 10100 10100 10100 10100 10100
				10100 10100 10100 10100 10100 10100 10100 10100 10100 10100 10100 10100 10100 10100 10100 10100 10100 10100
				10100 10100 10100 10100 10100 10100 10100 10100 10100 10100 10100 10100 10100 10100 10100 10100 10100 10100
				10100 10100 10100 10100 10100 10100 10100 10100 10100 10100 10100 10100 10100 10100 10100 10100 10100 10100
				10100 10100 10100 10100 10100 10100 10100 10100 10100 10100 10100 10100 10100 10100 10100 10100 10100 10100
				10100 10100 10100 10100 10100 10100 10100 10100 10100 10100 10100 10100 10100 10100 10100 10100 10100 10100
				10100 10100 10100 10100 10100 10100 10100 10100 10100 10100 10100 10100 10100 10100 10100 10100 10100 10100
				10100 10100 10100 10100 10100 10100 10100 10100 10100 10100 10100 10100 10100 10100 10100 10100 10100 10100
				10100 10100 10100 10100 10100 10100 10100 10100 10100 10100 10100 10100 10100 10100 10100 10100 10100 10100
				10100 10100 10100 10100 10100 10100 10100 10100 10100 10100 10100 10100 10100 10100 10100 10100 10100 10100
				10100 10100 10100 10100 10100 10100 10100 10100 10100 10100 10100 10100 10100 10100 10100 10100 10100 10100
				10100 10100 10100 10100 10100 10100 10100 10100 10100 10100 10100 10100 10100 10100 10100 10100 10100 10100
				10100 10100 10100 10100 10100 10100 10100 10100 10100 10100 10100 10100 10100 10100 10100 10100 10100 10100
				10100 10100 10100 10100 10100 10100 10100 10100 10100 10100 10100 10100 10100 10100 10100 10100 10100 10100
				10100 10100 10100 10100 10100 10100 10100 10100 10100 10100 10100 10100 10100 10100 10100 10100 10100 10100
				10100 10100 10100 10100 10100 10100 10100 10100 10100 10100 10100 10100 10100 10100 10100 10100 10100 10100
				10100 10100 10100 10100 10100 10100 10100 10100 10100 10100 10100 10100 10100 10100 10100 10100 10100 10100
				10100 10100 10100 10100 10100 10100 10100 10100 10100 10100 10100 10100 10100 10100 10100 10100 10100 10100
				10100 10100 10100 10100 10100 10100 10100 10100 10100 10100 10100 10100 10100 10100 10100 10100 10100 10100
				10100 10100 10100 10100 10100 10100 10100 10100 10100 10100 10100 10100 10100 10100 10100 10100 10100 10100
				10100 10100 10100 10100 10100 10100 10100 10100 10100 10100 10100 10100 10100 10100 10100 10100 10100 10100
				10100 10100 10100 10100 10100 10100 10100 10100 10100 10100 10100 10100 10100 10100 10100 10100 10100 10100
				10100 10100 10100 10100 10100 10100 10100 10100 10100 10100 10100 10100 10100 10100 10100 10100 10100 10100
				10100 10100 10100 10100 10100 10100 10100 10100 10100 10100 10100 10100 10100 10100 10100 10100 10100 10100
				10100 10100 10100 10100 10100 10100 10100 10100 10100 10100 10100 10100 10100 10100 10100 10100 10100 10100
				10100 10100 10100 10100 10100 10100 10100 10100 10100 10100 10100 10100 10100 10100 10100 10100 10100 10100
				10100 10100 10100 10100 10100 10100 10100 10100 10100 10100 10100 10100 10100 10100 10100 10100 10100 10100
				10100 10100 10100 10100 10100 10100 10100 10100 10100 10100 10100 10100 10100 10100 10100 10100 10100 10100
				10100 10100 10100 10100 10100 10100 10100 10100 10100 10100 10100 10100 10100 10100 10100 10100 10100 10100
				10100 10100 10100 10100 10100 10100 10100 10100 10100 10100 10100 10100 10100 10100 10100 10100 10100 10100
				10000 10000 10000>;

			PS_Config_Lmt_Open_Rawdata_P = <
				3049 3094 3224 3318 3372 3418 3495 3547 3532 3516 3542 3497 3445 3406 3372 3291 3196 3178
				3157 3183 3306 3409 3463 3509 3582 3633 3607 3592 3626 3563 3507 3460 3407 3320 3232 3182
				3137 3197 3305 3438 3495 3549 3626 3684 3649 3612 3627 3575 3523 3497 3451 3351 3262 3242
				3164 3196 3304 3425 3481 3526 3591 3638 3711 3654 3606 3561 3518 3500 3465 3369 3273 3234
				3211 3225 3358 3487 3553 3591 3669 3711 3785 3768 3672 3621 3588 3571 3532 3428 3347 3316
				3249 3222 3346 3470 3536 3572 3649 3684 3745 3796 3710 3654 3614 3582 3530 3423 3332 3290
				3234 3235 3379 3500 3570 3623 3694 3738 3805 3778 3663 3617 3586 3563 3516 3430 3340 3309
				3330 3267 3423 3543 3626 3670 3736 3780 3845 3848 3724 3697 3662 3633 3567 3477 3381 3332
				3315 3333 3442 3574 3661 3708 3778 3838 3906 3938 3826 3773 3735 3718 3651 3556 3463 3427
				3411 3396 3488 3617 3696 3736 3796 3841 3896 3960 3864 3796 3753 3729 3662 3567 3472 3423
				3375 3381 3451 3609 3707 3746 3819 3854 3915 4009 3907 3792 3795 3771 3703 3603 3518 3460
				3455 3424 3525 3633 3738 3780 3855 3894 3957 3998 3918 3844 3794 3760 3682 3572 3490 3427
				3409 3423 3529 3634 3740 3794 3857 3900 3955 4043 3953 3894 3844 3815 3738 3655 3571 3516
				3505 3479 3574 3663 3771 3817 3869 3906 3956 4072 3997 3942 3883 3848 3749 3662 3568 3501
				3504 3528 3624 3710 3859 3908 3983 4034 4092 4065 3983 3931 3847 3857 3774 3689 3606 3543
				3528 3512 3585 3693 3792 3837 3889 3936 3984 4078 4020 3962 3900 3861 3768 3680 3595 3516
				3473 3480 3572 3684 3789 3838 3900 3950 4011 4125 4062 4006 3956 3910 3816 3721 3656 3575
				3558 3529 3623 3735 3822 3887 3950 3997 4051 4135 4090 4029 3959 3885 3805 3710 3645 3554
				3535 3553 3599 3641 3656 3724 3798 3843 3879 3872 3819 3766 3715 3648 3635 3581 3546 3606
				3529 3539 3582 3617 3645 3680 3740 3787 3844 3946 3878 3815 3752 3687 3648 3591 3561 3606
				3567 3596 3644 3687 3726 3763 3816 3876 3925 3942 3893 3848 3791 3739 3690 3638 3595 3654
				3612 3620 3665 3712 3740 3739 3812 3859 3934 3959 3896 3852 3789 3745 3673 3654 3607 3638
				3609 3641 3700 3759 3798 3823 3876 3928 3994 3950 3897 3854 3801 3771 3724 3669 3637 3672
				3600 3623 3675 3731 3767 3788 3824 3869 3939 4009 3952 3901 3838 3794 3752 3680 3642 3652
				3595 3631 3689 3738 3770 3794 3834 3882 3942 3962 3918 3876 3824 3789 3752 3691 3651 3682
				3673 3701 3757 3802 3829 3851 3858 3922 4001 3973 3922 3873 3824 3778 3735 3644 3621 3620
				3649 3698 3745 3801 3829 3857 3889 3928 3992 3971 3924 3885 3823 3791 3743 3694 3628 3659
				3626 3654 3698 3747 3780 3809 3838 3879 3967 4019 3955 3911 3845 3806 3750 3689 3614 3617
				3614 3675 3733 3795 3830 3855 3897 3911 4005 3984 3929 3889 3831 3802 3763 3700 3617 3652
				3633 3658 3710 3763 3791 3810 3851 3894 3969 4023 3962 3922 3857 3820 3777 3710 3635 3620
				3619 3666 3743 3794 3823 3857 3887 3922 3976 4012 3957 3924 3871 3837 3796 3743 3665 3666
				3648 3659 3733 3782 3816 3847 3876 3918 3988 4029 3969 3928 3873 3829 3785 3735 3644 3624
				3602 3638 3710 3763 3791 3816 3845 3882 3922 4022 3964 3939 3883 3861 3819 3775 3683 3658
				3609 3729 3813 3873 3911 3943 3984 4026 4092 4162 4096 4057 3990 3955 3914 3859 3753 3603
				3435 3710 3822 3886 3931 3959 4013 4047 4102 4167 4099 4057 3999 3976 3931 3875 3770 3470
				3309 3661 3810 3866 3904 3931 3983 4015 4074 4146 4076 4016 3953 3914 3873 3809 3651 3229
				5120 5120 5120>;

			PS_Config_Lmt_Open_Rawdata_N = <
				1306 1326 1381 1422 1445 1465 1498 1520 1513 1507 1518 1498 1476 1459 1445 1410 1369 1362
				1353 1364 1417 1461 1484 1504 1535 1557 1546 1539 1554 1527 1503 1483 1460 1423 1385 1363
				1344 1370 1416 1473 1498 1521 1554 1579 1564 1548 1554 1532 1510 1498 1479 1436 1398 1389
				1356 1369 1416 1468 1492 1511 1539 1559 1590 1566 1545 1526 1507 1500 1485 1444 1402 1386
				1376 1382 1439 1494 1522 1539 1572 1590 1622 1615 1573 1552 1537 1530 1513 1469 1434 1421
				1392 1381 1434 1487 1515 1531 1564 1579 1605 1627 1590 1566 1549 1535 1513 1467 1428 1410
				1386 1386 1448 1500 1530 1552 1583 1602 1630 1619 1570 1550 1537 1527 1507 1470 1431 1418
				1427 1400 1467 1518 1554 1573 1601 1620 1648 1649 1596 1584 1569 1557 1528 1490 1449 1428
				1420 1428 1475 1531 1569 1589 1619 1645 1674 1687 1639 1617 1600 1593 1564 1524 1484 1468
				1462 1455 1495 1550 1584 1601 1627 1646 1669 1697 1656 1627 1608 1598 1569 1528 1488 1467
				1446 1449 1479 1546 1588 1605 1636 1651 1678 1718 1674 1625 1626 1616 1587 1544 1507 1483
				1480 1467 1510 1557 1602 1620 1652 1669 1696 1713 1679 1647 1626 1611 1578 1531 1495 1468
				1461 1467 1512 1557 1603 1626 1653 1671 1695 1732 1694 1669 1647 1635 1602 1566 1530 1507
				1502 1491 1531 1570 1616 1636 1658 1674 1695 1745 1713 1689 1664 1649 1606 1569 1529 1500
				1501 1512 1553 1590 1654 1675 1707 1729 1753 1742 1707 1684 1648 1653 1617 1581 1545 1518
				1512 1505 1536 1582 1625 1644 1666 1687 1707 1747 1723 1698 1671 1654 1615 1577 1540 1507
				1488 1491 1531 1579 1624 1645 1671 1693 1719 1768 1741 1717 1695 1675 1635 1594 1567 1532
				1525 1512 1552 1600 1638 1666 1693 1713 1736 1772 1753 1726 1696 1665 1630 1590 1562 1523
				1515 1522 1542 1560 1567 1596 1627 1647 1662 1659 1636 1614 1592 1563 1558 1534 1519 1545
				1512 1516 1535 1550 1562 1577 1603 1623 1647 1691 1662 1635 1608 1580 1563 1539 1526 1545
				1528 1541 1561 1580 1597 1612 1635 1661 1682 1689 1668 1649 1624 1602 1581 1559 1540 1566
				1548 1551 1570 1591 1603 1602 1633 1654 1686 1696 1669 1651 1624 1605 1574 1566 1546 1559
				1546 1560 1585 1611 1627 1638 1661 1683 1711 1693 1670 1651 1629 1616 1596 1572 1558 1573
				1543 1552 1575 1599 1614 1623 1639 1658 1688 1718 1693 1672 1645 1626 1608 1577 1561 1565
				1540 1556 1581 1602 1615 1626 1643 1663 1689 1698 1679 1661 1639 1624 1608 1582 1564 1578
				1574 1586 1610 1629 1641 1650 1653 1681 1714 1702 1681 1660 1639 1619 1600 1561 1552 1551
				1564 1585 1605 1629 1641 1653 1666 1683 1711 1702 1681 1665 1638 1624 1604 1583 1555 1568
				1554 1566 1585 1606 1620 1632 1645 1662 1700 1722 1695 1676 1648 1631 1607 1581 1549 1550
				1549 1575 1600 1626 1641 1652 1670 1676 1716 1707 1684 1666 1642 1629 1612 1585 1550 1565
				1557 1567 1590 1612 1624 1633 1650 1669 1701 1724 1698 1681 1653 1637 1618 1590 1558 1551
				1551 1571 1604 1626 1638 1653 1666 1681 1704 1719 1696 1681 1659 1644 1627 1604 1570 1571
				1563 1568 1600 1621 1635 1648 1661 1679 1709 1726 1701 1683 1660 1641 1622 1600 1561 1553
				1543 1559 1590 1612 1624 1635 1648 1663 1681 1723 1699 1688 1664 1654 1636 1618 1578 1567
				1546 1598 1634 1660 1676 1690 1707 1725 1753 1783 1755 1738 1710 1695 1677 1654 1608 1544
				1472 1590 1638 1665 1684 1696 1720 1734 1758 1786 1756 1738 1714 1704 1684 1660 1615 1487
				1418 1569 1633 1657 1673 1684 1707 1720 1746 1777 1747 1721 1694 1677 1660 1632 1564 1384
				(-511) (-511) (-511)>;

			PS_Config_Lmt_FW_Rawdata_P = <
				1135 1099 1099 1106 1113 1100 1104 1107 1143 1107 1115 1124 1113 1124 1114 1121 1122 1115
				1134 1100 1104 1114 1100 1110 1111 1131 1114 1131 1131 1106 1114 1117 1118 1120 1135 1136
				1118 1106 1103 1096 1097 1101 1106 1108 1096 1110 1089 1092 1104 1134 1090 1093 1136 1101
				1111 1111 1135 1115 1103 1120 1120 1106 1106 1117 1128 1129 1111 1122 1106 1100 1114 1114
				1104 1118 1127 1132 1118 1129 1139 1114 1129 1108 1108 1101 1099 1121 1104 1103 1101 1136
				1124 1129 1114 1118 1115 1114 1121 1114 1118 1134 1097 1092 1087 1083 1092 1101 1093 1114
				1100 1111 1101 1106 1106 1104 1106 1108 1110 1132 1129 1122 1122 1127 1117 1125 1127 1107
				1132 1110 1115 1103 1121 1092 1124 1129 1117 1103 1135 1134 1131 1136 1138 1129 1128 1138
				1108 1103 1097 1101 1110 1111 1108 1110 1101 1121 1113 1132 1135 1141 1131 1138 1134 1107
				1110 1107 1115 1111 1118 1093 1108 1138 1136 1120 1129 1115 1108 1101 1107 1104 1108 1097
				1107 1139 1118 1122 1122 1132 1115 1125 1127 1120 1124 1117 1108 1114 1120 1113 1120 1122
				1097 1138 1145 1139 1138 1104 1128 1121 1120 1085 1135 1129 1093 1099 1122 1103 1113 1097
				1104 1120 1115 1114 1124 1104 1118 1107 1110 1124 1110 1108 1103 1104 1108 1106 1111 1135
				1153 1101 1101 1108 1120 1117 1106 1111 1111 1150 1083 1086 1083 1108 1087 1124 1122 1139
				1120 1115 1096 1107 1090 1114 1114 1128 1121 1132 1120 1124 1096 1103 1111 1092 1096 1127
				1121 1099 1117 1115 1117 1118 1111 1110 1134 1132 1108 1101 1108 1107 1110 1120 1113 1118
				1129 1118 1114 1124 1131 1136 1138 1090 1093 1132 1121 1128 1141 1117 1113 1115 1118 1100
				1135 1107 1121 1136 1142 1145 1141 1114 1082 1110 1131 1125 1099 1136 1124 1125 1138 1103
				1096 1113 1103 1110 1106 1132 1122 1110 1111 1089 1082 1086 1127 1129 1118 1146 1131 1111
				1094 1101 1103 1094 1101 1122 1107 1100 1117 1110 1111 1108 1103 1114 1103 1100 1107 1134
				1141 1113 1107 1113 1107 1113 1106 1113 1099 1110 1141 1122 1124 1114 1131 1117 1117 1110
				1117 1121 1121 1128 1129 1129 1118 1136 1122 1118 1117 1121 1118 1107 1120 1106 1117 1114
				1110 1114 1115 1108 1113 1121 1115 1110 1124 1107 1127 1131 1128 1124 1127 1131 1129 1100
				1094 1106 1103 1118 1103 1106 1131 1127 1101 1117 1115 1108 1106 1117 1113 1121 1108 1120
				1107 1128 1129 1124 1132 1124 1110 1107 1111 1131 1121 1117 1121 1100 1108 1115 1117 1120
				1127 1115 1115 1118 1107 1100 1125 1122 1100 1107 1141 1108 1103 1093 1090 1103 1124 1136
				1160 1082 1083 1078 1078 1079 1101 1104 1131 1114 1117 1107 1101 1113 1106 1115 1110 1111
				1096 1120 1125 1111 1118 1117 1129 1143 1097 1108 1103 1125 1128 1113 1117 1120 1117 1097
				1131 1125 1120 1115 1125 1118 1131 1117 1106 1110 1113 1110 1117 1113 1115 1115 1110 1125
				1122 1136 1146 1134 1135 1139 1138 1106 1120 1114 1132 1117 1124 1134 1120 1114 1103 1121
				1139 1107 1106 1103 1113 1104 1114 1113 1101 1114 1087 1101 1090 1110 1100 1097 1108 1096
				1149 1124 1099 1149 1092 1145 1099 1129 1138 1128 1132 1103 1103 1107 1111 1113 1113 1113
				1132 1117 1090 1117 1106 1118 1093 1114 1120 1108 1115 1127 1118 1117 1115 1120 1111 1128
				1101 1113 1110 1114 1121 1113 1124 1117 1113 1113 1106 1128 1122 1120 1114 1125 1125 1106
				1118 1110 1122 1111 1128 1110 1125 1110 1127 1113 1139 1131 1141 1142 1139 1118 1139 1121
				1099 1115 1103 1099 1125 1108 1118 1152 1111 1090 1135 1094 1127 1093 1141 1129 1146 1141
				2560 2560 2560>;

			PS_Config_Lmt_FW_Rawdata_N = <
				486 471 471 474 477 471 473 474 490 474 478 481 477 481 477 480 481 478
				486 471 473 477 471 475 476 484 477 484 484 474 477 478 479 480 486 487
				479 474 472 469 470 472 474 475 469 475 466 468 473 486 467 468 487 472
				476 476 486 478 472 480 480 474 474 478 483 484 476 481 474 471 477 477
				473 479 483 485 479 484 488 477 484 475 475 472 471 480 473 472 472 487
				481 484 477 479 478 477 480 477 479 486 470 468 466 464 468 472 468 477
				471 476 472 474 474 473 474 475 475 485 484 481 481 483 478 482 483 474
				485 475 478 472 480 468 481 484 478 472 486 486 484 487 487 484 483 487
				475 472 470 472 475 476 475 475 472 480 477 485 486 489 484 487 486 474
				475 474 478 476 479 468 475 487 487 480 484 478 475 472 474 473 475 470
				474 488 479 481 481 485 478 482 483 480 481 478 475 477 480 477 480 481
				470 487 490 488 487 473 483 480 480 465 486 484 468 471 481 472 477 470
				473 480 478 477 481 473 479 474 475 481 475 475 472 473 475 474 476 486
				494 472 472 475 480 478 474 476 476 493 464 465 464 475 466 481 481 488
				480 478 469 474 467 477 477 483 480 485 480 481 469 472 476 468 469 483
				480 471 478 478 478 479 476 475 486 485 475 472 475 474 475 480 477 479
				484 479 477 481 484 487 487 467 468 485 480 483 489 478 477 478 479 471
				486 474 480 487 489 490 489 477 463 475 484 482 471 487 481 482 487 472
				469 477 472 475 474 485 481 475 476 466 463 465 483 484 479 491 484 476
				469 472 472 469 472 481 474 471 478 475 476 475 472 477 472 471 474 486
				489 477 474 477 474 477 474 477 471 475 489 481 481 477 484 478 478 475
				478 480 480 483 484 484 479 487 481 479 478 480 479 474 480 474 478 477
				475 477 478 475 477 480 478 475 481 474 483 484 483 481 483 484 484 471
				469 474 472 479 472 474 484 483 472 478 478 475 474 478 477 480 475 480
				474 483 484 481 485 481 475 474 476 484 480 478 480 471 475 478 478 480
				483 478 478 479 474 471 482 481 471 474 489 475 472 468 467 472 481 487
				497 463 464 462 462 462 472 473 484 477 478 474 472 477 474 478 475 476
				469 480 482 476 479 478 484 490 470 475 472 482 483 477 478 480 478 470
				484 482 480 478 482 479 484 478 474 475 477 475 478 477 478 478 475 482
				481 487 491 486 486 488 487 474 480 477 485 478 481 486 480 477 472 480
				488 474 474 472 477 473 477 477 472 477 466 472 467 475 471 470 475 469
				492 481 471 492 468 490 471 484 487 483 485 472 472 474 476 477 477 477
				485 478 467 478 474 479 468 477 480 475 478 483 479 478 478 480 476 483
				472 477 475 477 480 477 481 478 477 477 474 483 481 480 477 482 482 474
				479 475 481 476 483 475 482 475 483 477 488 484 489 489 488 479 488 480
				471 478 472 471 482 475 479 493 476 467 486 469 483 468 489 484 491 489
				240 240 240>;

			PS_Config_Lmt_FW_CC_P = <
				53 55 55 55 55 55 55 55 56 56 55 55 55 55 55 55 55 55
				55 53 53 53 53 55 55 55 57 56 55 53 53 53 53 53 53 55
				53 53 53 53 53 53 53 53 56 56 55 55 53 53 55 55 53 55
				55 53 53 53 53 53 53 55 56 56 53 53 53 53 53 53 53 55
				55 53 53 53 53 53 53 53 55 55 53 53 53 53 53 53 53 55
				55 53 53 53 53 55 53 55 56 55 53 53 53 53 53 53 53 55
				55 53 53 53 53 53 53 53 55 55 53 53 53 53 53 53 53 55
				55 53 55 53 53 55 53 55 56 56 53 53 53 53 53 53 53 55
				55 53 53 53 53 53 53 53 55 56 55 55 53 53 53 53 53 55
				55 55 55 55 55 55 55 55 56 56 55 53 53 53 53 53 53 55
				55 55 53 53 53 53 53 55 56 56 53 53 53 53 53 53 53 55
				55 55 53 55 53 55 55 55 56 56 53 53 53 53 53 53 53 55
				55 53 53 53 53 53 53 55 56 55 55 55 55 55 55 55 55 55
				55 55 55 55 55 55 55 56 57 55 55 55 55 53 55 53 53 55
				55 53 53 53 53 55 55 55 56 55 55 55 55 55 55 55 55 55
				55 53 55 55 55 55 55 56 57 55 55 55 55 53 55 53 53 55
				55 53 53 53 53 53 53 55 56 55 55 55 55 55 55 53 55 55
				55 53 55 55 55 55 55 56 57 55 53 55 55 53 53 53 53 56
				55 53 53 53 53 55 53 53 53 57 55 55 53 53 53 53 53 55
				56 55 55 55 55 55 55 55 55 57 56 55 55 55 55 55 53 55
				55 53 53 53 53 53 55 53 55 56 55 55 55 53 55 53 53 55
				56 55 55 55 53 55 55 55 55 57 55 55 55 53 55 53 53 55
				55 53 53 53 53 53 53 53 53 56 55 55 55 55 55 55 55 55
				56 55 55 55 55 55 55 55 56 56 55 53 53 53 53 53 53 55
				55 53 53 53 53 53 55 55 56 56 55 55 55 55 55 55 55 55
				55 53 53 53 53 53 55 55 56 57 55 55 55 55 55 55 55 55
				55 55 55 55 55 55 55 55 56 56 55 55 55 55 55 55 55 56
				56 55 55 55 55 55 55 55 57 56 55 55 55 53 53 55 53 55
				55 55 55 55 55 55 55 55 56 56 55 55 55 55 55 55 55 56
				56 55 55 55 55 55 55 55 56 56 55 53 55 53 53 53 55 55
				55 55 55 55 55 55 55 55 56 56 55 55 55 55 55 55 55 56
				56 55 55 55 55 55 55 55 57 56 55 55 55 55 55 55 53 56
				55 53 55 53 55 53 55 53 56 56 55 55 55 55 55 55 55 55
				56 55 55 55 55 55 55 55 57 57 55 55 53 53 53 55 53 55
				55 55 55 55 55 55 55 55 56 57 55 55 55 55 55 55 55 55
				55 55 55 55 55 55 55 55 57 57 55 55 55 55 55 55 55 53
				314 314 314>;

			PS_Config_Lmt_FW_CC_N = <
				24 24 24 24 24 24 24 24 25 25 24 24 24 24 24 24 24 24
				24 24 24 24 24 24 24 24 26 25 24 24 24 24 24 24 24 24
				24 24 24 24 24 24 24 24 25 25 24 24 24 24 24 24 24 24
				24 24 24 24 24 24 24 24 25 25 24 24 24 24 24 24 24 24
				24 24 24 24 24 24 24 24 24 24 24 24 24 24 24 24 24 24
				24 24 24 24 24 24 24 24 25 24 24 24 24 24 24 24 24 24
				24 24 24 24 24 24 24 24 24 24 24 24 24 24 24 24 24 24
				24 24 24 24 24 24 24 24 25 25 24 24 24 24 24 24 24 24
				24 24 24 24 24 24 24 24 24 25 24 24 24 24 24 24 24 24
				24 24 24 24 24 24 24 24 25 25 24 24 24 24 24 24 24 24
				24 24 24 24 24 24 24 24 25 25 24 24 24 24 24 24 24 24
				24 24 24 24 24 24 24 24 25 25 24 24 24 24 24 24 24 24
				24 24 24 24 24 24 24 24 25 24 24 24 24 24 24 24 24 24
				24 24 24 24 24 24 24 25 26 24 24 24 24 24 24 24 24 24
				24 24 24 24 24 24 24 24 25 24 24 24 24 24 24 24 24 24
				24 24 24 24 24 24 24 25 26 24 24 24 24 24 24 24 24 24
				24 24 24 24 24 24 24 24 25 24 24 24 24 24 24 24 24 24
				24 24 24 24 24 24 24 25 26 24 24 24 24 24 24 24 24 25
				24 24 24 24 24 24 24 24 24 26 24 24 24 24 24 24 24 24
				25 24 24 24 24 24 24 24 24 26 25 24 24 24 24 24 24 24
				24 24 24 24 24 24 24 24 24 25 24 24 24 24 24 24 24 24
				25 24 24 24 24 24 24 24 24 26 24 24 24 24 24 24 24 24
				24 24 24 24 24 24 24 24 24 25 24 24 24 24 24 24 24 24
				25 24 24 24 24 24 24 24 25 25 24 24 24 24 24 24 24 24
				24 24 24 24 24 24 24 24 25 25 24 24 24 24 24 24 24 24
				24 24 24 24 24 24 24 24 25 26 24 24 24 24 24 24 24 24
				24 24 24 24 24 24 24 24 25 25 24 24 24 24 24 24 24 25
				25 24 24 24 24 24 24 24 26 25 24 24 24 24 24 24 24 24
				24 24 24 24 24 24 24 24 25 25 24 24 24 24 24 24 24 25
				25 24 24 24 24 24 24 24 25 25 24 24 24 24 24 24 24 24
				24 24 24 24 24 24 24 24 25 25 24 24 24 24 24 24 24 25
				25 24 24 24 24 24 24 24 26 25 24 24 24 24 24 24 24 25
				24 24 24 24 24 24 24 24 25 25 24 24 24 24 24 24 24 24
				25 24 24 24 24 24 24 24 26 26 24 24 24 24 24 24 24 24
				24 24 24 24 24 24 24 24 25 26 24 24 24 24 24 24 24 24
				24 24 24 24 24 24 24 24 26 26 24 24 24 24 24 24 24 24
				0 0 0>;

			PS_Config_Lmt_FW_Diff_P = <
				50 50 50 50 50 50 50 50 50 50 50 50 50 50 50 50 50 50
				50 50 50 50 50 50 50 50 50 50 50 50 50 50 50 50 50 50
				50 50 50 50 50 50 50 50 50 50 50 50 50 50 50 50 50 50
				50 50 50 50 50 50 50 50 50 50 50 50 50 50 50 50 50 50
				50 50 50 50 50 50 50 50 50 50 50 50 50 50 50 50 50 50
				50 50 50 50 50 50 50 50 50 50 50 50 50 50 50 50 50 50
				50 50 50 50 50 50 50 50 50 50 50 50 50 50 50 50 50 50
				50 50 50 50 50 50 50 50 50 50 50 50 50 50 50 50 50 50
				50 50 50 50 50 50 50 50 50 50 50 50 50 50 50 50 50 50
				50 50 50 50 50 50 50 50 50 50 50 50 50 50 50 50 50 50
				50 50 50 50 50 50 50 50 50 50 50 50 50 50 50 50 50 50
				50 50 50 50 50 50 50 50 50 50 50 50 50 50 50 50 50 50
				50 50 50 50 50 50 50 50 50 50 50 50 50 50 50 50 50 50
				50 50 50 50 50 50 50 50 50 50 50 50 50 50 50 50 50 50
				50 50 50 50 50 50 50 50 50 50 50 50 50 50 50 50 50 50
				50 50 50 50 50 50 50 50 50 50 50 50 50 50 50 50 50 50
				50 50 50 50 50 50 50 50 50 50 50 50 50 50 50 50 50 50
				50 50 50 50 50 50 50 50 50 50 50 50 50 50 50 50 50 50
				50 50 50 50 50 50 50 50 50 50 50 50 50 50 50 50 50 50
				50 50 50 50 50 50 50 50 50 50 50 50 50 50 50 50 50 50
				50 50 50 50 50 50 50 50 50 50 50 50 50 50 50 50 50 50
				50 50 50 50 50 50 50 50 50 50 50 50 50 50 50 50 50 50
				50 50 50 50 50 50 50 50 50 50 50 50 50 50 50 50 50 50
				50 50 50 50 50 50 50 50 50 50 50 50 50 50 50 50 50 50
				50 50 50 50 50 50 50 50 50 50 50 50 50 50 50 50 50 50
				50 50 50 50 50 50 50 50 50 50 50 50 50 50 50 50 50 50
				50 50 50 50 50 50 50 50 50 50 50 50 50 50 50 50 50 50
				50 50 50 50 50 50 50 50 50 50 50 50 50 50 50 50 50 50
				50 50 50 50 50 50 50 50 50 50 50 50 50 50 50 50 50 50
				50 50 50 50 50 50 50 50 50 50 50 50 50 50 50 50 50 50
				50 50 50 50 50 50 50 50 50 50 50 50 50 50 50 50 50 50
				50 50 50 50 50 50 50 50 50 50 50 50 50 50 50 50 50 50
				50 50 50 50 50 50 50 50 50 50 50 50 50 50 50 50 50 50
				50 50 50 50 50 50 50 50 50 50 50 50 50 50 50 50 50 50
				50 50 50 50 50 50 50 50 50 50 50 50 50 50 50 50 50 50
				50 50 50 50 50 50 50 50 50 50 50 50 50 50 50 50 50 50
				75 75 75>;

			PS_Config_Lmt_FW_Diff_N = <
				(-50) (-50) (-50) (-50) (-50) (-50) (-50) (-50) (-50) (-50) (-50) (-50) (-50) (-50) (-50) (-50) (-50) (-50)
				(-50) (-50) (-50) (-50) (-50) (-50) (-50) (-50) (-50) (-50) (-50) (-50) (-50) (-50) (-50) (-50) (-50) (-50)
				(-50) (-50) (-50) (-50) (-50) (-50) (-50) (-50) (-50) (-50) (-50) (-50) (-50) (-50) (-50) (-50) (-50) (-50)
				(-50) (-50) (-50) (-50) (-50) (-50) (-50) (-50) (-50) (-50) (-50) (-50) (-50) (-50) (-50) (-50) (-50) (-50)
				(-50) (-50) (-50) (-50) (-50) (-50) (-50) (-50) (-50) (-50) (-50) (-50) (-50) (-50) (-50) (-50) (-50) (-50)
				(-50) (-50) (-50) (-50) (-50) (-50) (-50) (-50) (-50) (-50) (-50) (-50) (-50) (-50) (-50) (-50) (-50) (-50)
				(-50) (-50) (-50) (-50) (-50) (-50) (-50) (-50) (-50) (-50) (-50) (-50) (-50) (-50) (-50) (-50) (-50) (-50)
				(-50) (-50) (-50) (-50) (-50) (-50) (-50) (-50) (-50) (-50) (-50) (-50) (-50) (-50) (-50) (-50) (-50) (-50)
				(-50) (-50) (-50) (-50) (-50) (-50) (-50) (-50) (-50) (-50) (-50) (-50) (-50) (-50) (-50) (-50) (-50) (-50)
				(-50) (-50) (-50) (-50) (-50) (-50) (-50) (-50) (-50) (-50) (-50) (-50) (-50) (-50) (-50) (-50) (-50) (-50)
				(-50) (-50) (-50) (-50) (-50) (-50) (-50) (-50) (-50) (-50) (-50) (-50) (-50) (-50) (-50) (-50) (-50) (-50)
				(-50) (-50) (-50) (-50) (-50) (-50) (-50) (-50) (-50) (-50) (-50) (-50) (-50) (-50) (-50) (-50) (-50) (-50)
				(-50) (-50) (-50) (-50) (-50) (-50) (-50) (-50) (-50) (-50) (-50) (-50) (-50) (-50) (-50) (-50) (-50) (-50)
				(-50) (-50) (-50) (-50) (-50) (-50) (-50) (-50) (-50) (-50) (-50) (-50) (-50) (-50) (-50) (-50) (-50) (-50)
				(-50) (-50) (-50) (-50) (-50) (-50) (-50) (-50) (-50) (-50) (-50) (-50) (-50) (-50) (-50) (-50) (-50) (-50)
				(-50) (-50) (-50) (-50) (-50) (-50) (-50) (-50) (-50) (-50) (-50) (-50) (-50) (-50) (-50) (-50) (-50) (-50)
				(-50) (-50) (-50) (-50) (-50) (-50) (-50) (-50) (-50) (-50) (-50) (-50) (-50) (-50) (-50) (-50) (-50) (-50)
				(-50) (-50) (-50) (-50) (-50) (-50) (-50) (-50) (-50) (-50) (-50) (-50) (-50) (-50) (-50) (-50) (-50) (-50)
				(-50) (-50) (-50) (-50) (-50) (-50) (-50) (-50) (-50) (-50) (-50) (-50) (-50) (-50) (-50) (-50) (-50) (-50)
				(-50) (-50) (-50) (-50) (-50) (-50) (-50) (-50) (-50) (-50) (-50) (-50) (-50) (-50) (-50) (-50) (-50) (-50)
				(-50) (-50) (-50) (-50) (-50) (-50) (-50) (-50) (-50) (-50) (-50) (-50) (-50) (-50) (-50) (-50) (-50) (-50)
				(-50) (-50) (-50) (-50) (-50) (-50) (-50) (-50) (-50) (-50) (-50) (-50) (-50) (-50) (-50) (-50) (-50) (-50)
				(-50) (-50) (-50) (-50) (-50) (-50) (-50) (-50) (-50) (-50) (-50) (-50) (-50) (-50) (-50) (-50) (-50) (-50)
				(-50) (-50) (-50) (-50) (-50) (-50) (-50) (-50) (-50) (-50) (-50) (-50) (-50) (-50) (-50) (-50) (-50) (-50)
				(-50) (-50) (-50) (-50) (-50) (-50) (-50) (-50) (-50) (-50) (-50) (-50) (-50) (-50) (-50) (-50) (-50) (-50)
				(-50) (-50) (-50) (-50) (-50) (-50) (-50) (-50) (-50) (-50) (-50) (-50) (-50) (-50) (-50) (-50) (-50) (-50)
				(-50) (-50) (-50) (-50) (-50) (-50) (-50) (-50) (-50) (-50) (-50) (-50) (-50) (-50) (-50) (-50) (-50) (-50)
				(-50) (-50) (-50) (-50) (-50) (-50) (-50) (-50) (-50) (-50) (-50) (-50) (-50) (-50) (-50) (-50) (-50) (-50)
				(-50) (-50) (-50) (-50) (-50) (-50) (-50) (-50) (-50) (-50) (-50) (-50) (-50) (-50) (-50) (-50) (-50) (-50)
				(-50) (-50) (-50) (-50) (-50) (-50) (-50) (-50) (-50) (-50) (-50) (-50) (-50) (-50) (-50) (-50) (-50) (-50)
				(-50) (-50) (-50) (-50) (-50) (-50) (-50) (-50) (-50) (-50) (-50) (-50) (-50) (-50) (-50) (-50) (-50) (-50)
				(-50) (-50) (-50) (-50) (-50) (-50) (-50) (-50) (-50) (-50) (-50) (-50) (-50) (-50) (-50) (-50) (-50) (-50)
				(-50) (-50) (-50) (-50) (-50) (-50) (-50) (-50) (-50) (-50) (-50) (-50) (-50) (-50) (-50) (-50) (-50) (-50)
				(-50) (-50) (-50) (-50) (-50) (-50) (-50) (-50) (-50) (-50) (-50) (-50) (-50) (-50) (-50) (-50) (-50) (-50)
				(-50) (-50) (-50) (-50) (-50) (-50) (-50) (-50) (-50) (-50) (-50) (-50) (-50) (-50) (-50) (-50) (-50) (-50)
				(-50) (-50) (-50) (-50) (-50) (-50) (-50) (-50) (-50) (-50) (-50) (-50) (-50) (-50) (-50) (-50) (-50) (-50)
				(-75) (-75) (-75)>;

			PS_Config_Diff_Test_Frame = <50>;
		};/*36672D tm Module*/
	};
};
/* TOUCH end */
